VERSION ""

NS_ :

BS_:

BU_: Gas_Snsr ABS EHBL LSC RSC HU BCM MCU BMS OBC
VAL_TABLE_ Theft_Detection_Enum 3 "Error" 2 "Theft_detected" 1 "No_theft_detected" 0 "SNA" ;
VAL_TABLE_ Reset_reason_Enum 4 "WTDG" 3 "SoftReset" 2 "HardReset" 1 "PowerOFF" 0 "SNA" ;
VAL_TABLE_ Wakeup_Reason_Enum 6 "IMU" 5 "Charger" 4 "RTC" 3 "LTE" 2 "BLE" 1 "SSB" 0 "SNA" ;
VAL_TABLE_ Tow_Tamper 2 "Tamper_Detected" 1 "Tow_Detected" 0 "No_Detection" ;
VAL_TABLE_ Crash 3 "High_Crash_Detected" 2 "Mid_Crash_Detected" 1 "Low_Crash_Detected" 0 "No_Crash" ;
VAL_TABLE_ Indicator_Flts 8 "LI_SC_RI_OC_Err" 7 "LI_OC_RI_SC_Err" 6 "LI_RI_SC_Err" 5 "LI_RI_OC_Err" 4 "RI_SC_Err" 3 "RI_OC_Err" 2 "LI_SC_Err" 1 "LI_OC_Err" 0 "No_Err" ;
VAL_TABLE_ Ride_mode_Limp 7 "LIMPHOME" 6 "OFFROAD" 5 "SPORT" 4 "CUSTOM" 3 "TOUR" 2 "RAIN" 1 "ECO" 0 "SNA" ;
VAL_TABLE_ Chrg_Amt 7 "100%" 6 "90%" 5 "80%" 4 "70%" 3 "60%" 2 "50%" 1 "40%" 0 "No_Sel" ;
VAL_TABLE_ Chrg_Rate 3 "Tickle" 2 "Standard" 1 "Rapid" 0 "No_Sel" ;
VAL_TABLE_ MSC_Cntrl_Mode 3 "Reserved" 2 "MTC Control Required" 1 "MDTC Control Required" 0 "No Control Required" ;
VAL_TABLE_ MTC_Lamp 6 "Signal Invalid" 5 "Cornering TC Fail" 4 "TC_User_Disabled" 3 "TC_Initialising" 2 "TC Error" 1 "TC Active Intervention" 0 "TC Not Active" ;
VAL_TABLE_ MTC_Mode 3 "High" 2 "Standard" 1 "Minimum" 0 "OFF" ;
VAL_TABLE_ Allowed 1 "Allowed" 0 "Denied" ;
VAL_TABLE_ Error 1 "Error" 0 "No Error" ;
VAL_TABLE_ Fault 1 "Fault" 0 "No Fault" ;
VAL_TABLE_ InProgress 3 "Invalid" 2 "Completed" 1 "InProgress" 0 "Not Active" ;
VAL_TABLE_ Valid 1 "Valid" 0 "Not Valid" ;
VAL_TABLE_ True_False 1 "True" 0 "False" ;
VAL_TABLE_ SNA_UNLOCK 1 "UNLOCK" 0 "SNA" ;
VAL_TABLE_ OFF_ON 1 "ON" 0 "OFF" ;
VAL_TABLE_ Ride_mode 6 "OFFROAD" 5 "SPORT" 4 "CUSTOM" 3 "TOUR" 2 "RAIN" 1 "ECO" 0 "SNA" ;
VAL_TABLE_ Wireless_Ch 6 "Phone_Overheating" 5 "Charger_Error" 4 "Foreign_Object_Detection" 3 "Charging" 2 "Charging_Completed" 1 "Standby" 0 "SNA" ;
VAL_TABLE_ Language_stt 6 "POR" 5 "ESP" 4 "FR" 3 "DE" 2 "US" 1 "UK" 0 "SNA" ;
VAL_TABLE_ SSB_Illumination_Mode 7 "
EHBL_Lock_Fail" 6 "EHBL_Lock_Success" 5 "Charging_Complete
" 4 "Charging_Mode" 3 "Drive_Mode
" 2 "Park_Mode" 1 "Power_On
" 0 "SNA" ;

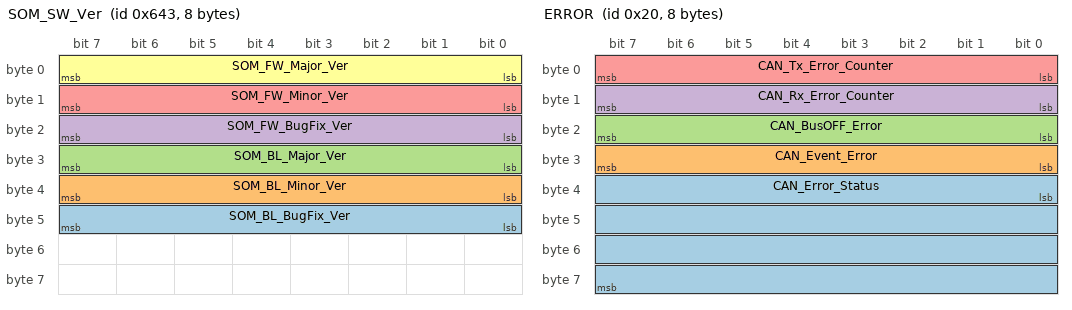
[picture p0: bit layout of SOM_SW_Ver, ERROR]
BO_ 1603 SOM_SW_Ver: 8 BCM
 SG_ SOM_BL_BugFix_Ver : 40|8@1+ (1,0) [0|255] "" Vector__XXX
 SG_ SOM_BL_Minor_Ver : 32|8@1+ (1,0) [0|255] "" Vector__XXX
 SG_ SOM_BL_Major_Ver : 24|8@1+ (1,0) [0|255] "" Vector__XXX
 SG_ SOM_FW_BugFix_Ver : 16|8@1+ (1,0) [0|255] "" Vector__XXX
 SG_ SOM_FW_Minor_Ver : 8|8@1+ (1,0) [0|255] "" Vector__XXX
 SG_ SOM_FW_Major_Ver : 0|8@1+ (1,0) [0|255] "" Vector__XXX

BO_ 1800 VCU_Data10: 8 BCM
 SG_ Reset_reason : 8|8@1+ (1,0) [0|255] "" Vector__XXX
 SG_ Wakeup_reason : 0|8@1+ (1,0) [0|255] "" Vector__XXX

BO_ 772 Diag: 8 BCM
 SG_ Diag : 0|8@1+ (1,0) [0|255] "" Vector__XXX

BO_ 32 ERROR: 8 BCM
 SG_ CAN_Error_Status : 32|32@1- (1,0) [0|0] "" Vector__XXX
 SG_ CAN_Event_Error : 24|8@1- (1,0) [0|0] "" Vector__XXX
 SG_ CAN_BusOFF_Error : 16|8@1- (1,0) [0|0] "" Vector__XXX
 SG_ CAN_Rx_Error_Counter : 8|8@1- (1,0) [0|0] "" Vector__XXX
 SG_ CAN_Tx_Error_Counter : 0|8@1- (1,0) [0|0] "" Vector__XXX

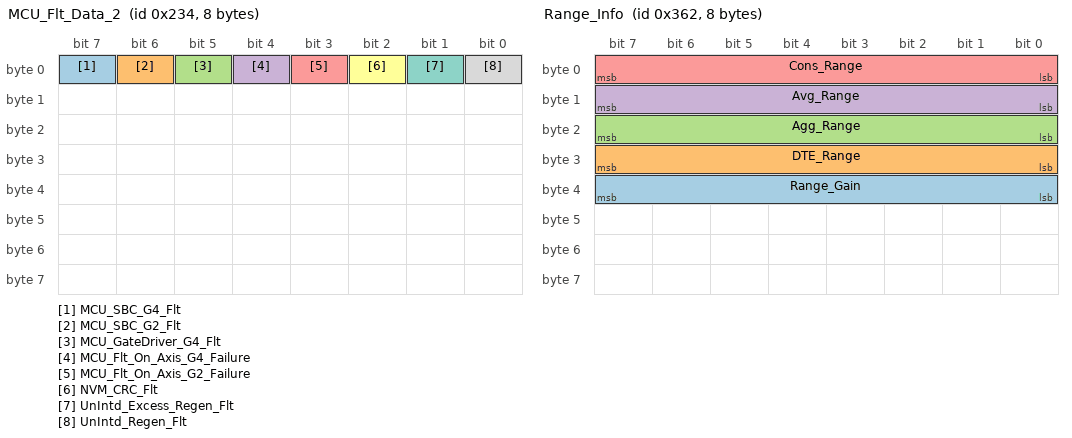
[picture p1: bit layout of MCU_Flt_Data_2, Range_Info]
BO_ 564 MCU_Flt_Data_2: 8 MCU
 SG_ MCU_SBC_G4_Flt : 7|1@1+ (1,0) [0|1] ""  BCM,HU
 SG_ MCU_SBC_G2_Flt : 6|1@1+ (1,0) [0|1] ""  BCM,HU
 SG_ MCU_GateDriver_G4_Flt : 5|1@1+ (1,0) [0|1] ""  BCM,HU
 SG_ MCU_Flt_On_Axis_G4_Failure : 4|1@1+ (1,0) [0|1] ""  BCM,HU
 SG_ MCU_Flt_On_Axis_G2_Failure : 3|1@1+ (1,0) [0|1] ""  BCM,HU
 SG_ NVM_CRC_Flt : 2|1@1+ (1,0) [0|1] ""  BCM,HU
 SG_ UnIntd_Excess_Regen_Flt : 1|1@1+ (1,0) [0|1] ""  BCM,HU
 SG_ UnIntd_Regen_Flt : 0|1@1+ (1,0) [0|1] ""  BCM,HU

BO_ 769 CS1_HSD: 8 BCM
 SG_ CS_Parameter4 : 48|16@1+ (1,0) [0|65535] "mV" Vector__XXX
 SG_ CS_Parameter3 : 32|16@1+ (1,0) [0|65535] "mV" Vector__XXX
 SG_ CS_Parameter2 : 16|16@1+ (1,0) [0|65535] "mV" Vector__XXX
 SG_ CS_Parameter1 : 0|16@1+ (1,0) [0|65535] "mV" Vector__XXX

BO_ 2015 Func_Diag_ID: 8 Vector__XXX

BO_ 315 Traction_Info: 8 ABS
 SG_ MDTC_Torque_Req : 32|16@1- (0.01,0) [-327|326] "Nm"  BCM,MCU
 SG_ MTC_Torque_Req : 16|16@1- (0.01,0) [-327|326] "Nm"  BCM,MCU
 SG_ MSC_Trq_Ctrl_mode : 0|2@1+ (1,0) [0|3] ""  MCU,BCM

BO_ 571 MCU_Data_7: 8 MCU
 SG_ Active_ShrtCkt_Sts : 48|2@1+ (1,0) [0|3] ""  BCM
 SG_ MCU_DC_Bus_Vlt_2 : 16|16@1+ (0.01,0) [0|655.35] "V"  BCM
 SG_ MCU_DC_Bus_Vlt_3 : 32|16@1+ (0.01,0) [0|655.35] "V"  BCM
 SG_ MCU_DC_Bus_Vlt_1 : 0|16@1+ (0.01,0) [0|655.35] "V"  BCM

BO_ 866 Range_Info: 8 BCM
 SG_ Range_Gain : 32|8@1+ (1,0) [0|255] "km"  HU
 SG_ DTE_Range : 24|8@1+ (1,0) [0|255] "km"  HU
 SG_ Agg_Range : 16|8@1+ (1,0) [0|255] "km"  HU
 SG_ Avg_Range : 8|8@1+ (1,0) [0|255] "km"  HU
 SG_ Cons_Range : 0|8@1+ (1,0) [0|255] "km"  HU

BO_ 2023 BCM_Diagnostic_Request: 8 Vector__XXX
 SG_ BCM_Diag_Request : 0|64@1+ (1,0) [0|1.84467440737096E+19] ""  BCM

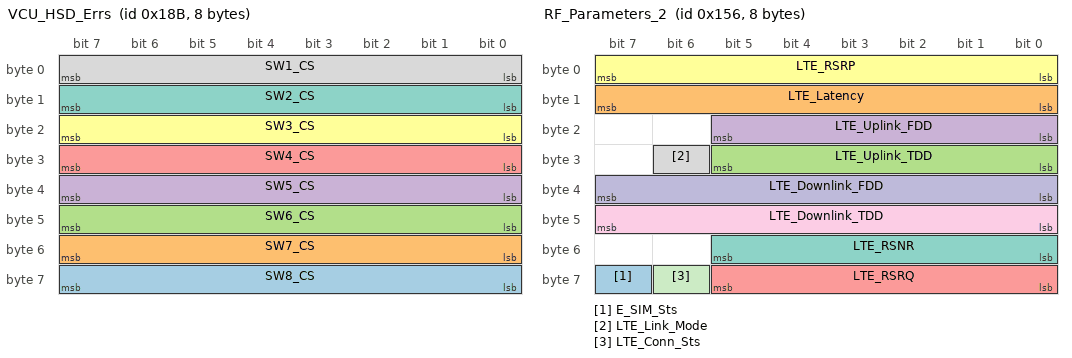
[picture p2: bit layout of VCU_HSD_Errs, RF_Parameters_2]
BO_ 395 VCU_HSD_Errs: 8 BCM
 SG_ SW8_CS : 56|8@1+ (1,0) [0|255] "" Vector__XXX
 SG_ SW7_CS : 48|8@1+ (1,0) [0|255] "" Vector__XXX
 SG_ SW6_CS : 40|8@1+ (1,0) [0|255] "" Vector__XXX
 SG_ SW5_CS : 32|8@1+ (1,0) [0|255] "" Vector__XXX
 SG_ SW4_CS : 24|8@1+ (1,0) [0|255] "" Vector__XXX
 SG_ SW3_CS : 16|8@1+ (1,0) [0|255] "" Vector__XXX
 SG_ SW2_CS : 8|8@1+ (1,0) [0|255] "" Vector__XXX
 SG_ SW1_CS : 0|8@1+ (1,0) [0|255] "" Vector__XXX

BO_ 342 RF_Parameters_2: 8 BCM
 SG_ E_SIM_Sts : 63|1@1+ (1,0) [0|1] "" Vector__XXX
 SG_ LTE_Latency : 8|8@1+ (1,0) [0|255] "ms" Vector__XXX
 SG_ LTE_Uplink_TDD : 24|6@1+ (1,0) [0|63] "mbps" Vector__XXX
 SG_ LTE_Uplink_FDD : 16|6@1+ (1,0) [0|63] "mbps" Vector__XXX
 SG_ LTE_RSRQ : 56|6@1+ (1,-60) [-60|3] "dB" Vector__XXX
 SG_ LTE_RSRP : 0|8@1+ (1,-120) [-120|135] "dBm" Vector__XXX
 SG_ LTE_RSNR : 48|6@1+ (1,0) [0|63] "mbps" Vector__XXX
 SG_ LTE_Link_Mode : 30|1@1+ (1,0) [0|1] "" Vector__XXX
 SG_ LTE_Downlink_TDD : 40|8@1+ (1,0) [0|255] "mbps" Vector__XXX
 SG_ LTE_Downlink_FDD : 32|8@1+ (1,0) [0|255] "mbps" Vector__XXX
 SG_ LTE_Conn_Sts : 62|1@1+ (1,0) [0|1] "" Vector__XXX

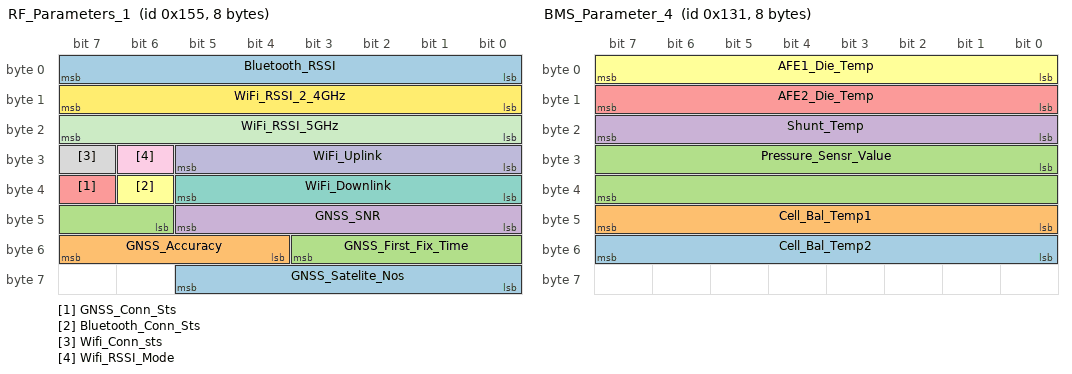
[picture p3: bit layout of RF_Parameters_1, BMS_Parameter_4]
BO_ 341 RF_Parameters_1: 8 BCM
 SG_ GNSS_Satelite_Nos : 56|6@1+ (1,0) [0|63] "" Vector__XXX
 SG_ GNSS_Accuracy : 52|4@1+ (1,0) [0|15] "m" Vector__XXX
 SG_ GNSS_First_Fix_Time : 46|6@1+ (1,0) [0|63] "secs" Vector__XXX
 SG_ GNSS_SNR : 40|6@1+ (1,-60) [-60|3] "dB" Vector__XXX
 SG_ GNSS_Conn_Sts : 39|1@1+ (1,0) [0|1] "" Vector__XXX
 SG_ Bluetooth_Conn_Sts : 38|1@1+ (1,0) [0|1] "" Vector__XXX
 SG_ WiFi_Downlink : 32|6@1+ (1,0) [0|63] "mbps" Vector__XXX
 SG_ Wifi_Conn_sts : 31|1@1+ (1,0) [0|1] "" Vector__XXX
 SG_ Wifi_RSSI_Mode : 30|1@1+ (1,0) [0|1] "" Vector__XXX
 SG_ WiFi_Uplink : 24|6@1+ (1,0) [0|63] "mbps" Vector__XXX
 SG_ WiFi_RSSI_5GHz : 16|8@1+ (1,-120) [-120|135] "dBm" Vector__XXX
 SG_ WiFi_RSSI_2_4GHz : 8|8@1+ (1,-120) [-120|135] "dBm" Vector__XXX
 SG_ Bluetooth_RSSI : 0|8@1+ (1,-120) [-120|135] "dBm" Vector__XXX

BO_ 305 BMS_Parameter_4: 8 BMS
 SG_ Cell_Bal_Temp2 : 48|8@1+ (1,-40) [-40|150] "degC"  BCM
 SG_ Cell_Bal_Temp1 : 40|8@1+ (1,-40) [-40|150] "degC"  BCM
 SG_ Pressure_Sensr_Value : 24|16@1+ (1,0) [0|315] "kPa"  BCM
 SG_ Shunt_Temp : 16|8@1+ (1,-20) [-20|120] "degC"  BCM
 SG_ AFE2_Die_Temp : 8|8@1+ (1,-40) [-40|150] "degC"  BCM
 SG_ AFE1_Die_Temp : 0|8@1+ (1,-40) [-40|150] "degC"  BCM

BO_ 394 VCU_Data9: 8 BCM
 SG_ Instant_Eff : 16|16@1+ (0.1,0) [0|6553.5] "Wh/Km"  HU
 SG_ Live_Odo : 0|16@1+ (0.1,0) [0|6553.5] "Km"  HU

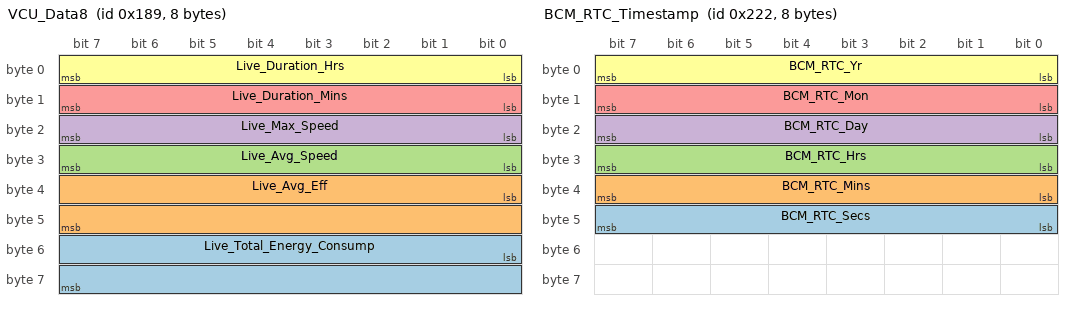
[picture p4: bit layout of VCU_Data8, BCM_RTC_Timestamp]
BO_ 393 VCU_Data8: 8 BCM
 SG_ Live_Total_Energy_Consump : 48|16@1+ (0.1,0) [0|6553.5] "kWh"  HU
 SG_ Live_Avg_Eff : 32|16@1+ (0.1,0) [0|6553.5] "Wh/Km"  HU
 SG_ Live_Avg_Speed : 24|8@1+ (1,0) [0|255] "Kmph"  HU
 SG_ Live_Max_Speed : 16|8@1+ (1,0) [0|255] "Kmph"  HU
 SG_ Live_Duration_Mins : 8|8@1+ (1,0) [0|255] "Mins"  HU
 SG_ Live_Duration_Hrs : 0|8@1+ (1,0) [0|255] "hrs"  HU

BO_ 546 BCM_RTC_Timestamp: 8 BCM
 SG_ BCM_RTC_Secs : 40|8@1+ (1,0) [0|255] ""  HU
 SG_ BCM_RTC_Mins : 32|8@1+ (1,0) [0|255] ""  HU
 SG_ BCM_RTC_Hrs : 24|8@1+ (1,0) [0|255] ""  HU
 SG_ BCM_RTC_Day : 16|8@1+ (1,0) [0|255] ""  HU
 SG_ BCM_RTC_Mon : 8|8@1+ (1,0) [0|255] ""  HU
 SG_ BCM_RTC_Yr : 0|8@1+ (1,0) [0|255] ""  HU

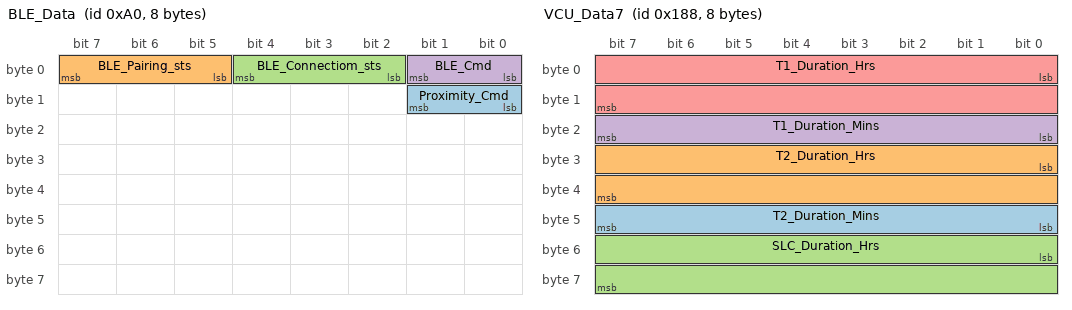
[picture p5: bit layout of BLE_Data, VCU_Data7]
BO_ 160 BLE_Data: 8 BCM
 SG_ Proximity_Cmd : 8|2@1+ (1,0) [0|3] "" Vector__XXX
 SG_ BLE_Pairing_sts : 5|3@1+ (1,0) [0|7] "" Vector__XXX
 SG_ BLE_Connectiom_sts : 2|3@1+ (1,0) [0|7] "" Vector__XXX
 SG_ BLE_Cmd : 0|2@1+ (1,0) [0|3] "" Vector__XXX

BO_ 392 VCU_Data7: 8 BCM
 SG_ T2_Duration_Mins : 40|8@1+ (1,0) [0|255] "mins"  HU
 SG_ T2_Duration_Hrs : 24|16@1+ (1,0) [0|65535] "hrs"  HU
 SG_ SLC_Duration_Hrs : 48|16@1+ (1,0) [0|65535] "hrs"  HU
 SG_ T1_Duration_Mins : 16|8@1+ (1,0) [0|255] "Mins"  HU
 SG_ T1_Duration_Hrs : 0|16@1+ (1,0) [0|65535] "hrs"  HU

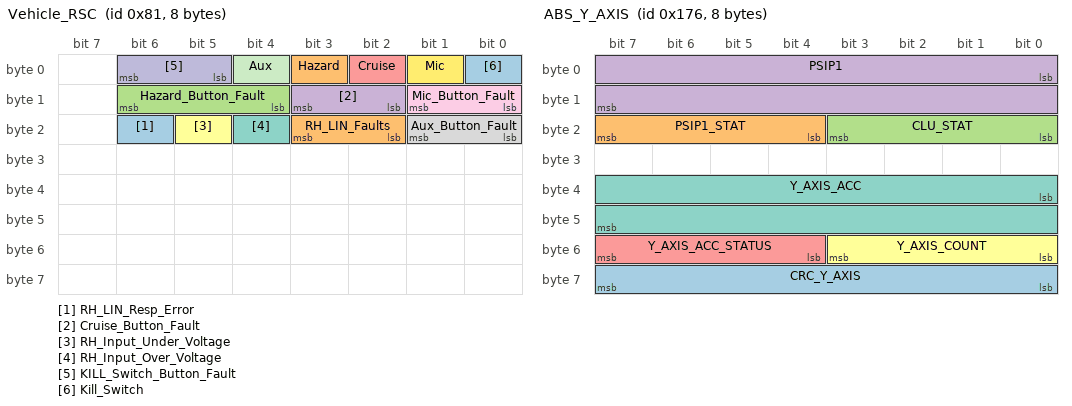
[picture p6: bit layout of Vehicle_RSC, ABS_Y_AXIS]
BO_ 129 Vehicle_RSC: 8 BCM
 SG_ RH_LIN_Resp_Error : 22|1@1+ (1,0) [0|1] "" Vector__XXX
 SG_ RH_LIN_Faults : 18|2@1+ (1,0) [0|3] "" Vector__XXX
 SG_ Hazard_Button_Fault : 12|3@1+ (1,0) [0|3] "" Vector__XXX
 SG_ Cruise_Button_Fault : 10|2@1+ (1,0) [0|1] "" Vector__XXX
 SG_ Cruise : 2|1@1+ (1,0) [0|1] "" Vector__XXX
 SG_ RH_Input_Under_Voltage : 21|1@1+ (1,0) [0|1] "" Vector__XXX
 SG_ RH_Input_Over_Voltage : 20|1@1+ (1,0) [0|1] "" Vector__XXX
 SG_ Aux_Button_Fault : 16|2@1+ (1,0) [0|3] "" Vector__XXX
 SG_ Mic_Button_Fault : 8|2@1+ (1,0) [0|3] "" Vector__XXX
 SG_ KILL_Switch_Button_Fault : 5|2@1+ (1,0) [0|3] "" Vector__XXX
 SG_ Aux : 4|1@1+ (1,0) [0|1] "" Vector__XXX
 SG_ Mic : 1|1@1+ (1,0) [0|1] "" Vector__XXX
 SG_ Kill_Switch : 0|1@1+ (1,0) [0|1] "" Vector__XXX
 SG_ Hazard : 3|1@1+ (1,0) [0|1] "" Vector__XXX

BO_ 128 Vehicle_LSC: 8 BCM
 SG_ LH_LIN_Resp_Error : 60|1@1+ (1,0) [0|1] "" Vector__XXX
 SG_ LH_LIN_Faults : 56|2@1+ (1,0) [0|7] "" Vector__XXX
 SG_ Mode_Down_Button_Fault : 43|3@1+ (1,0) [0|3] "" Vector__XXX
 SG_ Mode_Up_Button_Fault : 40|3@1+ (1,0) [0|3] "" Vector__XXX
 SG_ Pass_Beam_Button_Fault : 24|3@1+ (1,0) [0|3] "" Vector__XXX
 SG_ High_Beam_Button_Fault : 19|3@1+ (1,0) [0|3] "" Vector__XXX
 SG_ Home_Button_Fault : 16|3@1+ (1,0) [0|3] "" Vector__XXX
 SG_ LH_Input_Under_Voltage : 59|1@1+ (1,0) [0|1] "" Vector__XXX
 SG_ LH_Input_Over_Voltage : 58|1@1+ (1,0) [0|1] "" Vector__XXX
 SG_ RH_Ind_Button_Fault : 52|2@1+ (1,0) [0|3] "" Vector__XXX
 SG_ LH_Ind_Button_Fault : 50|2@1+ (1,0) [0|3] "" Vector__XXX
 SG_ Ok_Button_Fault : 48|2@1+ (1,0) [0|3] "" Vector__XXX
 SG_ Right_JoyStick_Button_Fault : 34|2@1+ (1,0) [0|3] "" Vector__XXX
 SG_ Up_JoyStick_Button_Fault : 36|2@1+ (1,0) [0|3] "" Vector__XXX
 SG_ Left_JoyStick_Button_Fault : 32|2@1+ (1,0) [0|3] "" Vector__XXX
 SG_ Horn_Button_Fault : 13|2@1+ (1,0) [0|3] "" Vector__XXX
 SG_ Down_JoyStick_Button_Fault : 38|2@1+ (1,0) [0|3] "" Vector__XXX
 SG_ RH_Ind : 12|1@1+ (1,0) [0|1] "" Vector__XXX
 SG_ LH_Ind : 11|1@1+ (1,0) [0|1] "" Vector__XXX
 SG_ OK_Btn : 10|1@1+ (1,0) [0|1] "" Vector__XXX
 SG_ Mode_Dwn_Selector : 9|1@1+ (1,0) [0|1] "" Vector__XXX
 SG_ Mode_Up_Selector : 8|1@1+ (1,0) [0|1] "" Vector__XXX
 SG_ Down_Joy_Stick : 7|1@1+ (1,0) [0|1] "" Vector__XXX
 SG_ Up_Joy_Stick : 6|1@1+ (1,0) [0|1] "" Vector__XXX
 SG_ Right_Joy_Stick : 5|1@1+ (1,0) [0|1] "" Vector__XXX
 SG_ Left_Joy_Stick : 4|1@1+ (1,0) [0|1] "" Vector__XXX
 SG_ Pass_beam : 3|1@1+ (1,0) [0|1] "" Vector__XXX
 SG_ High_beam : 2|1@1+ (1,0) [0|1] "" Vector__XXX
 SG_ Home : 1|1@1+ (1,0) [0|1] "" Vector__XXX
 SG_ Horn : 0|1@1+ (1,0) [0|1] "" Vector__XXX

BO_ 374 ABS_Y_AXIS: 8 ABS
 SG_ CRC_Y_AXIS : 56|8@1+ (1,0) [0|255] ""  BCM
 SG_ PSIP1_STAT : 20|4@1+ (1,0) [0|15] ""  BCM
 SG_ CLU_STAT : 16|4@1+ (1,0) [0|15] ""  BCM
 SG_ PSIP1 : 0|16@1+ (0.005,-163.84) [-163.84|163.835] "deg/sec"  BCM
 SG_ Y_AXIS_ACC_STATUS : 52|4@1+ (1,0) [0|15] ""  BCM
 SG_ Y_AXIS_COUNT : 48|4@1+ (1,0) [0|15] ""  BCM
 SG_ Y_AXIS_ACC : 32|16@1+ (0.00125,-40.957) [-40.957|40.958] "m/s^2"  BCM

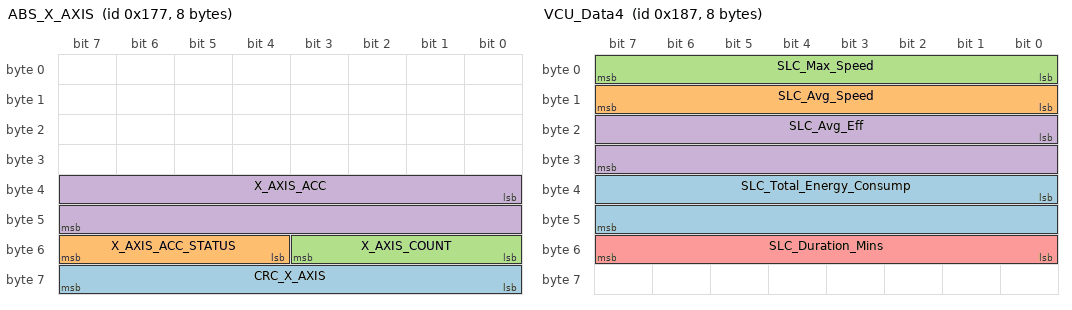
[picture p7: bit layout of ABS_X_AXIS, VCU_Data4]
BO_ 375 ABS_X_AXIS: 8 ABS
 SG_ CRC_X_AXIS : 56|8@1+ (1,0) [0|255] ""  BCM
 SG_ X_AXIS_ACC_STATUS : 52|4@1+ (1,0) [0|15] ""  BCM
 SG_ X_AXIS_COUNT : 48|4@1+ (1,0) [0|15] ""  BCM
 SG_ X_AXIS_ACC : 32|16@1+ (0.00125,-40.957) [-40.957|40.958] "m/s^2"  BCM

BO_ 565 MCU_Data_6: 8 MCU
 SG_ OnAxix_3_3_Vlt : 16|8@1+ (0.1,0) [0|25.5] "V"  BCM
 SG_ Regen_sts : 8|3@1+ (1,0) [0|4] ""  BCM,HU
 SG_ Motor_Power : 0|8@1+ (1,0) [0|255] "Kw"  HU,BCM

BO_ 391 VCU_Data4: 8 BCM
 SG_ SLC_Total_Energy_Consump : 32|16@1+ (0.1,0) [0|6553.5] "kWh"  HU
 SG_ SLC_Avg_Speed : 8|8@1+ (1,0) [0|255] "Kmph"  HU
 SG_ SLC_Max_Speed : 0|8@1+ (1,0) [0|255] "Kmph"  HU
 SG_ SLC_Avg_Eff : 16|16@1+ (0.1,0) [0|6553.5] "Wh/Km"  HU
 SG_ SLC_Duration_Mins : 48|8@1+ (1,0) [0|255] "Mins"  HU

BO_ 390 VCU_Data3: 8 BCM
 SG_ T2_Avg_Eff : 16|16@1+ (0.1,0) [0|6553.5] "Wh/Km"  HU
 SG_ T2_Avg_Speed : 8|8@1+ (1,0) [0|255] "Kmph"  HU
 SG_ T2_Max_Speed : 0|8@1+ (1,0) [0|255] "Kmph"  HU
 SG_ T2_Total_Energy_Consump : 32|16@1+ (0.1,0) [0|6553.5] "kWh"  HU

BO_ 373 VCU_Data2: 8 BCM
 SG_ T1_Total_Energy_Consump : 32|16@1+ (0.1,0) [0|6553.5] "kWh"  HU
 SG_ T1_Avg_Eff : 16|16@1+ (0.1,0) [0|6553.5] "Wh/Km"  HU
 SG_ T1_Avg_Speed : 8|8@1+ (1,0) [0|255] "Kmph"  HU
 SG_ T1_Max_Speed : 0|8@1+ (1,0) [0|255] "Kmph"  HU

BO_ 377 VCU_Data6: 8 BCM
 SG_ Trip2_Odo : 32|32@1+ (0.1,0) [0|429496729.5] "Km"  HU
 SG_ Trip1_Odo : 0|32@1+ (0.1,0) [0|429496729.5] "Km"  HU

BO_ 376 VCU_Data5: 8 BCM
 SG_ SLC_Odo : 32|32@1+ (0.1,0) [0|429496729.5] "Km"  HU
 SG_ Odometer : 0|32@1+ (1,0) [0|4294967295] "Km"  HU

BO_ 1229 EHBL_SW_VER: 8 EHBL
 SG_ EHBL_FW_BugFix_Ver : 16|8@1+ (1,0) [0|255] ""  BCM
 SG_ EHBL_FW_Minor_Ver : 8|8@1+ (1,0) [0|255] ""  BCM
 SG_ EHBL_FW_Major_Ver : 0|8@1+ (1,0) [0|255] ""  BCM

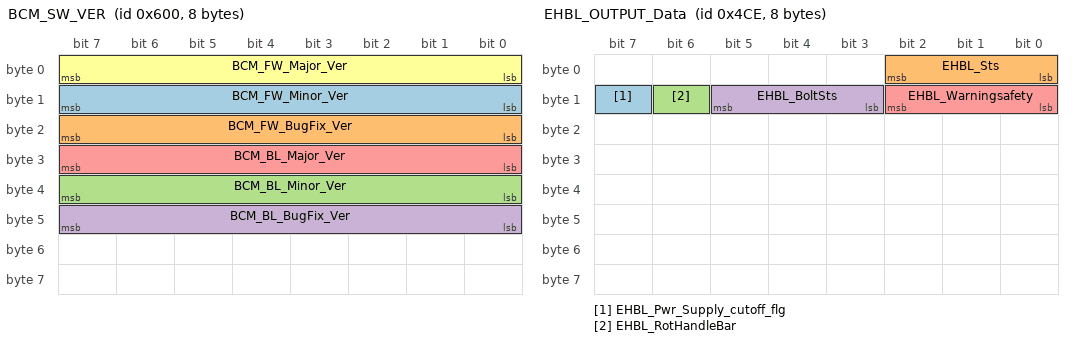
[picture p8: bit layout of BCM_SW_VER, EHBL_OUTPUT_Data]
BO_ 1536 BCM_SW_VER: 8 BCM
 SG_ BCM_FW_Minor_Ver : 8|8@1+ (1,0) [0|255] "" Vector__XXX
 SG_ BCM_FW_BugFix_Ver : 16|8@1+ (1,0) [0|255] "" Vector__XXX
 SG_ BCM_BL_Minor_Ver : 32|8@1+ (1,0) [0|255] "" Vector__XXX
 SG_ BCM_BL_BugFix_Ver : 40|8@1+ (1,0) [0|255] "" Vector__XXX
 SG_ BCM_BL_Major_Ver : 24|8@1+ (1,0) [0|255] "" Vector__XXX
 SG_ BCM_FW_Major_Ver : 0|8@1+ (1,0) [0|255] "" Vector__XXX

BO_ 1230 EHBL_OUTPUT_Data: 8 EHBL
 SG_ EHBL_Pwr_Supply_cutoff_flg : 15|1@1+ (1,0) [0|1] ""  BCM
 SG_ EHBL_Sts : 0|3@1+ (1,0) [0|7] ""  BCM
 SG_ EHBL_RotHandleBar : 14|1@1+ (1,0) [0|1] ""  BCM
 SG_ EHBL_BoltSts : 11|3@1+ (1,0) [0|7] ""  BCM
 SG_ EHBL_Warningsafety : 8|3@1+ (1,0) [0|7] ""  BCM

BO_ 1618 EHBL_to_VCU_Auth_Response: 8 EHBL
 SG_ EHBL_Auth_Result : 8|8@1+ (1,0) [0|255] ""  BCM

BO_ 1104 VCU_TO_ABS: 8 BCM
 SG_ MTC_Requested_Mode : 8|3@1+ (1,0) [0|4] ""  ABS
 SG_ ABS_Requested_Mode : 4|4@1+ (1,0) [0|15] ""  ABS
 SG_ Variant_Info : 0|4@1+ (1,0) [0|15] ""  ABS

BO_ 576 ABS_Flt_Info: 8 ABS
 SG_ IMU_Model_Monitoring : 23|1@1+ (1,0) [0|1] ""  BCM
 SG_ IMU_Wrong_Mount_Fail : 22|1@1+ (1,0) [0|1] ""  BCM
 SG_ CAN_Buss_Off_Fail : 17|1@1+ (1,0) [0|1] ""  BCM
 SG_ CAN_IMU_Signal_Fail : 21|1@1+ (1,0) [0|1] ""  BCM
 SG_ CAN_IMU_Frame_Fail : 20|1@1+ (1,0) [0|1] ""  BCM
 SG_ CAN_Frame : 19|1@1+ (1,0) [0|1] ""  BCM
 SG_ CAN_Controller_Generic_Fail : 18|1@1+ (1,0) [0|1] ""  BCM
 SG_ WSS_Generic_Fail : 16|1@1+ (1,0) [0|1] ""  BCM
 SG_ WSS_Suspicious_Fail_R : 15|1@1+ (1,0) [0|1] ""  BCM
 SG_ WSS_Suspicious_Fail_F : 14|1@1+ (1,0) [0|1] ""  BCM
 SG_ WSS_Plausibility_Fail_R : 13|1@1+ (1,0) [0|1] ""  BCM
 SG_ WSS_Plausibility_Fail_F : 12|1@1+ (1,0) [0|1] ""  BCM
 SG_ WSS_HW_Fail_R : 11|1@1+ (1,0) [0|1] ""  BCM
 SG_ WSS_HW_Fail_F : 10|1@1+ (1,0) [0|1] ""  BCM
 SG_ Pump_Motor_Reversible_Fail : 9|1@1+ (1,0) [0|1] ""  BCM
 SG_ Pump_Motor_Fail : 8|1@1+ (1,0) [0|1] ""  BCM
 SG_ UZ_Supply_UV_Flt : 7|1@1+ (1,0) [0|1] ""  BCM
 SG_ UZ_Supply_OV_Flt : 6|1@1+ (1,0) [0|1] ""  BCM
 SG_ Outlet_Valve_Fail_R : 5|1@1+ (1,0) [0|1] ""  BCM
 SG_ Outlet_Valve_Fail_F : 4|1@1+ (1,0) [0|1] ""  BCM
 SG_ Inlet_Valve_Fail_R : 3|1@1+ (1,0) [0|1] ""  BCM
 SG_ Inlet_Valve_Fail_F : 2|1@1+ (1,0) [0|1] ""  BCM
 SG_ Valve_Relay_Flt : 1|1@1+ (1,0) [0|1] ""  BCM
 SG_ Control_Unit_Fail : 0|1@1+ (1,0) [0|1] ""  BCM

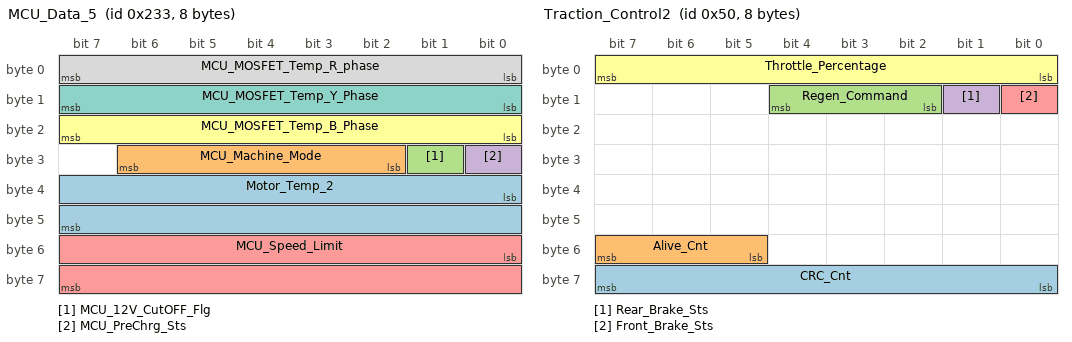
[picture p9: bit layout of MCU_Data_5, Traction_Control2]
BO_ 563 MCU_Data_5: 8 MCU
 SG_ Motor_Temp_2 : 32|16@1+ (0.01,-55) [-55|600.35] "degC"  BCM
 SG_ MCU_Machine_Mode : 26|5@1+ (1,0) [0|31] ""  HU,BCM
 SG_ MCU_12V_CutOFF_Flg : 25|1@1+ (1,0) [0|1] ""  BCM
 SG_ MCU_PreChrg_Sts : 24|1@1+ (1,0) [0|1] ""  BCM
 SG_ MCU_Speed_Limit : 48|16@1- (1,0) [-32768|32767] ""  BCM
 SG_ MCU_MOSFET_Temp_B_Phase : 16|8@1+ (1,-55) [-55|200] ""  BCM
 SG_ MCU_MOSFET_Temp_Y_Phase : 8|8@1+ (1,-55) [-55|200] ""  BCM
 SG_ MCU_MOSFET_Temp_R_phase : 0|8@1+ (1,-55) [-55|200] ""  BCM

BO_ 343 ISOLATION_Resistance_Monitor: 8 BMS
 SG_ Neg_Isolation_Resistance : 32|32@1+ (1,0) [0|4294967295] "Ohm"  BCM
 SG_ Pos_Isolation_Resistance : 0|32@1+ (1,0) [0|4294967295] "Ohm"  BCM

BO_ 340 SOM_Settings_Data: 8 BCM
 SG_ Theft_Detection : 38|2@1+ (1,0) [0|3] "" Vector__XXX
 SG_ SOM_CRateSel_PreConf : 30|2@1+ (1,0) [0|3] "" Vector__XXX
 SG_ SOM_Boot_Ack : 7|1@1+ (1,0) [0|1] "" Vector__XXX
 SG_ SOM_ChrgAmtSel_PreConf : 48|4@1+ (1,0) [0|15] "" Vector__XXX
 SG_ SOM_Chrg_Amt_Sel : 12|4@1+ (1,0) [0|15] "" Vector__XXX
 SG_ SOM_Chrg_Rate_Sel : 5|2@1+ (1,0) [0|3] "" Vector__XXX
 SG_ Language_Sel_Set : 8|3@1+ (1,0) [0|6] ""  HU
 SG_ Vacation_Mode : 0|1@1+ (1,0) [0|1] "" Vector__XXX
 SG_ Brightness_Level : 42|4@1+ (1,0) [0|15] ""  HU
 SG_ Trip_2_Reset_flg : 41|1@1+ (1,0) [0|1] "" Vector__XXX
 SG_ Trip_1_Reset_flg : 40|1@1+ (1,0) [0|1] "" Vector__XXX
 SG_ Day_Night_Mode_Sel : 46|2@1+ (1,0) [0|3] ""  HU
 SG_ Brightness_Sel : 2|1@1+ (1,0) [0|1] ""  HU
 SG_ ABS_Sensitivity_Sel : 21|2@1+ (1,0) [0|3] "" Vector__XXX
 SG_ ABS_State_Sel : 19|2@1+ (1,0) [0|3] ""  HU
 SG_ TPMS_Rear : 32|6@1+ (1,0) [0|63] "" Vector__XXX
 SG_ TPMS_Front : 24|6@1+ (1,0) [0|63] "" Vector__XXX
 SG_ Ride_Mode_Sel : 16|3@1+ (1,0) [0|7] "" Vector__XXX
 SG_ Hill_Hold_Setting : 4|1@1+ (1,0) [0|1] ""  ABS
 SG_ Haptic_Setting : 3|1@1+ (1,0) [0|1] "" Vector__XXX
 SG_ Regen_Setting : 1|1@1+ (1,0) [0|1] ""  ABS

BO_ 561 MCU_Data_3: 8 MCU
 SG_ Regen_Min_Speed : 48|14@1+ (1,0) [0|16383] "rpm"  BCM
 SG_ B_Phase_Curr_MCU : 32|16@1- (0.1,0) [-32768|32767] "A"  BCM
 SG_ Y_Phase_Curr_MCU : 16|16@1- (0.1,0) [-32768|32767] "A"  BCM
 SG_ R_Phase_Curr_MCU : 0|16@1- (0.1,0) [-32768|32767] "A"  BCM

BO_ 80 Traction_Control2: 8 BCM
 SG_ CRC_Cnt : 56|8@1+ (1,0) [0|255] ""  ABS
 SG_ Alive_Cnt : 53|3@1+ (1,0) [0|7] ""  ABS
 SG_ Regen_Command : 10|3@1+ (1,0) [0|4] ""  MCU
 SG_ Rear_Brake_Sts : 9|1@1+ (1,0) [0|1] ""  MCU
 SG_ Front_Brake_Sts : 8|1@1+ (1,0) [0|1] ""  MCU
 SG_ Throttle_Percentage : 0|8@1- (1,0) [-128|127] "%"  ABS,MCU

BO_ 2031 BCM_Diagnostic_Response: 8 BCM
 SG_ BCM_Diag_Response : 0|64@1+ (1,0) [0|1.84467440737096E+19] "" Vector__XXX

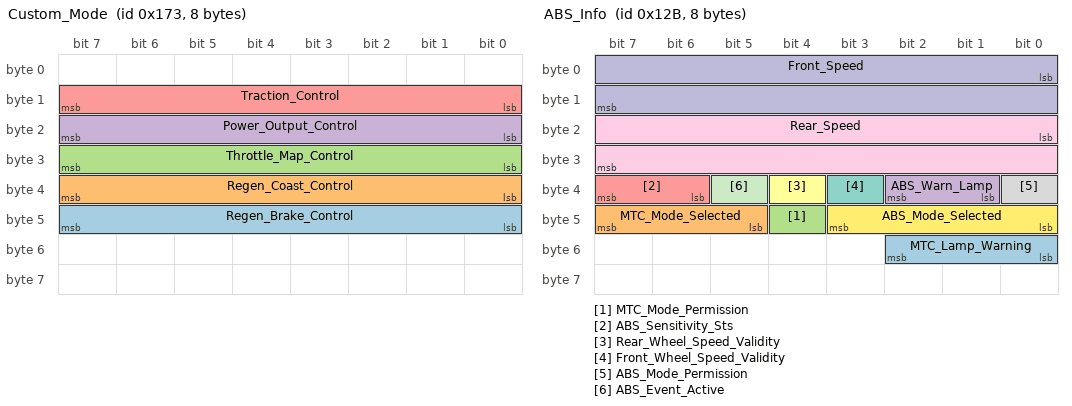
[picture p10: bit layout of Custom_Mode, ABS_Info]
BO_ 371 Custom_Mode: 8 BCM
 SG_ Regen_Brake_Control : 40|8@1+ (1,0) [0|255] ""  MCU
 SG_ Regen_Coast_Control : 32|8@1+ (1,0) [0|255] ""  MCU
 SG_ Throttle_Map_Control : 24|8@1+ (1,0) [0|255] ""  MCU
 SG_ Power_Output_Control : 16|8@1+ (1,0) [0|255] ""  MCU
 SG_ Traction_Control : 8|8@1+ (1,0) [0|255] ""  HU,MCU

BO_ 2027 EHBL_Diagnostic_Response: 8 EHBL
 SG_ EHBL_Diag_Response : 0|64@1+ (1,0) [0|1.84467440737096E+19] ""  BCM

BO_ 299 ABS_Info: 8 ABS
 SG_ MTC_Lamp_Warning : 48|3@1+ (1,0) [0|6] ""  BCM,HU
 SG_ MTC_Mode_Selected : 45|3@1+ (1,0) [0|4] ""  BCM
 SG_ MTC_Mode_Permission : 44|1@1+ (1,0) [0|1] ""  BCM
 SG_ ABS_Warn_Lamp : 33|2@1+ (1,0) [0|3] ""  HU,BCM
 SG_ ABS_Sensitivity_Sts : 38|2@1+ (1,0) [0|3] ""  BCM
 SG_ Rear_Wheel_Speed_Validity : 36|1@1+ (1,0) [0|1] ""  BCM
 SG_ Front_Wheel_Speed_Validity : 35|1@1+ (1,0) [0|1] ""  BCM
 SG_ ABS_Mode_Permission : 32|1@1+ (1,0) [0|1] ""  BCM
 SG_ Rear_Speed : 16|16@1+ (0.05625,0) [0|360] "kmph"  BCM
 SG_ Front_Speed : 0|16@1+ (0.05625,0) [0|360] "kmph"  BCM
 SG_ ABS_Event_Active : 37|1@1+ (1,0) [0|1] ""  BCM
 SG_ ABS_Mode_Selected : 40|4@1+ (1,0) [0|4] ""  HU,BCM

BO_ 1290 BMS_Flt_2: 8 BMS
 SG_ Temp_Imbalance_Warn : 52|1@1+ (1,0) [0|1] ""  BCM,HU
 SG_ BMS_LP_DCDC_Ovload_flt : 51|1@1+ (1,0) [0|1] ""  HU,BCM
 SG_ BMS_Vlt_Imbalance_flt : 50|1@1+ (1,0) [0|1] ""  HU,BCM
 SG_ BMS_Internal_Fault : 49|1@1+ (1,0) [0|1] ""  HU,BCM
 SG_ BMS_Prechrg_Overload : 48|1@1+ (1,0) [0|1] ""  HU,BCM
 SG_ BMS_OV_Permnt_Flt : 47|1@1+ (1,0) [0|1] ""  HU,BCM
 SG_ BMS_UV_Permnt_Flt : 46|1@1+ (1,0) [0|1] ""  HU,BCM
 SG_ Fire_Ext_Sts : 44|1@1+ (1,0) [0|1] ""  HU,BCM
 SG_ Pyro_Fuse_Sts : 43|1@1+ (1,0) [0|1] ""  HU,BCM
 SG_ Low_SOC_Warn_15 : 45|1@1+ (1,0) [0|1] ""  HU,BCM
 SG_ HVIL_OBC_Err : 39|1@1+ (1,0) [0|1] ""  HU,BCM
 SG_ HVIL_MCU_Err : 38|1@1+ (1,0) [0|1] ""  HU,BCM
 SG_ BMS_Dischrg_Fuse_Fail : 35|1@1+ (1,0) [0|1] ""  HU,BCM
 SG_ BMS_Chrgr_Fuse_Fail : 34|1@1+ (1,0) [0|1] ""  HU,BCM
 SG_ LPDCDC_OP_FAIL : 31|1@1+ (1,0) [0|1] ""  HU,BCM
 SG_ AFE1_Fail : 30|1@1+ (1,0) [0|1] ""  HU,BCM
 SG_ Pack_Monitor_Fail : 29|1@1+ (1,0) [0|1] ""  HU,BCM
 SG_ AFE_ISO_Fail_Err : 28|1@1+ (1,0) [0|1] ""  HU,BCM
 SG_ AFE_SPI_Heartbeat_Fail_Err : 27|1@1+ (1,0) [0|1] ""  HU,BCM
 SG_ LOW_SOC : 26|1@1+ (1,0) [0|1] ""  HU,BCM
 SG_ LOW_SOC_WARN : 25|1@1+ (1,0) [0|1] ""  HU,BCM
 SG_ HPDCDC_OP_FAIL : 24|1@1+ (1,0) [0|1] ""  HU,BCM
 SG_ Pos_Contactor_Weld : 23|1@1+ (1,0) [0|1] ""  BCM,HU
 SG_ PreChrg_Relay_Weld : 22|1@1+ (1,0) [0|1] ""  BCM,HU
 SG_ OBC_CAN_Heartbeat_Err : 21|1@1+ (1,0) [0|1] ""  BCM,HU
 SG_ VCU_CAN_Heartbeat_Err : 20|1@1+ (1,0) [0|1] ""  BCM,HU
 SG_ BMS_DisChrg_Over_Curr : 12|1@1+ (1,0) [0|1] ""  BCM,HU
 SG_ BMS_LPDCDC_CutOFF : 6|1@1+ (1,0) [0|1] ""  BCM,HU
 SG_ BMS_Low_Temp_during_Drv_Err : 3|1@1+ (1,0) [0|1] ""  HU,BCM
 SG_ BMS_PDU_Lock_HW : 16|1@1+ (1,0) [0|1] ""  BCM,HU
 SG_ BMS_Pressure_Snsr_Err : 42|1@1+ (1,0) [0|1] ""  HU,BCM
 SG_ BMS_Gas_Snsr_Err : 41|1@1+ (1,0) [0|1] ""  HU,BCM
 SG_ BMS_LP_DCDC_Output_Shrt_Ckt : 40|1@1+ (1,0) [0|1] ""  HU,BCM
 SG_ BMS_Cell_Temp_Imbalance : 18|1@1+ (1,0) [0|1] ""  BCM,HU
 SG_ BMS_Insulation_Monitor_Err : 17|1@1+ (1,0) [0|1] ""  BCM,HU
 SG_ BMS_PDU_Fail : 33|1@1+ (1,0) [0|1] ""  HU,BCM
 SG_ BMS_Thermal_Runaway : 19|1@1+ (1,0) [0|1] ""  BCM,HU
 SG_ BMS_PreChrg_No_Load_Detected : 15|1@1+ (1,0) [0|1] ""  BCM,HU
 SG_ BMS_Short_Ckt_Detect_Err : 32|1@1+ (1,0) [0|1] ""  HU,BCM
 SG_ BMS_Over_Temp_Drv_Err : 11|1@1+ (1,0) [0|1] ""  HU,BCM
 SG_ BMS_Over_Temp_Drv_Warn_Info : 10|1@1+ (1,0) [0|1] ""  HU,BCM
 SG_ BMS_Over_Temp_Chrg_Err : 9|1@1+ (1,0) [0|1] ""  HU,BCM
 SG_ BMS_Over_Temp_Chrg_Warn_Info : 8|1@1+ (1,0) [0|1] ""  HU,BCM
 SG_ BMS_Under_Vlt_Err : 5|1@1+ (1,0) [0|1] ""  HU,BCM
 SG_ BMS_Under_Vlt_Warn_Info : 4|1@1+ (1,0) [0|1] ""  HU,BCM
 SG_ BMS_Over_Vlt_Chrg_Err : 7|1@1+ (1,0) [0|1] ""  HU,BCM
 SG_ BMS_PreChrg_Fail : 14|1@1+ (1,0) [0|1] ""  HU,BCM
 SG_ BMS_Over_Curr_Chrg_Err : 13|1@1+ (1,0) [0|1] ""  HU,BCM
 SG_ BMS_Curr_Snsr_Fail_Shrt_Ckt : 37|1@1+ (1,0) [0|1] ""  HU,BCM
 SG_ BMS_Curr_Snsr_Fail_Open_Ckt : 36|1@1+ (1,0) [0|1] ""  HU,BCM
 SG_ BMS_Low_Temp_during_Drv_Warn : 2|1@1+ (1,0) [0|1] ""  BCM,HU
 SG_ BMS_Low_Temp_during_Chrg_Err : 1|1@1+ (1,0) [0|1] ""  HU,BCM
 SG_ BMS_Low_Temp_Chrg_Warn_info : 0|1@1+ (1,0) [0|1] ""  HU,BCM

BO_ 1289 BMS_Flt_1: 8 BMS
 SG_ BMS_BattPack_Temp6_Snsr_Fail : 33|1@1+ (1,0) [0|1] ""  HU,BCM
 SG_ BMS_BattPack_Temp5_Snsr_Fail : 32|1@1+ (1,0) [0|1] ""  HU,BCM
 SG_ BMS_BattPack_Temp4_Snsr_Fail : 31|1@1+ (1,0) [0|1] ""  HU,BCM
 SG_ BMS_BattPack_Temp3_Snsr_Fail : 30|1@1+ (1,0) [0|1] ""  HU,BCM
 SG_ BMS_BattPack_Temp2_Snsr_Fail : 29|1@1+ (1,0) [0|1] ""  HU,BCM
 SG_ BMS_BattPack_Temp1_Snsr_Fail : 28|1@1+ (1,0) [0|1] ""  HU,BCM
 SG_ BMS_Vlt_Snsr_Fail_Cell28 : 27|1@1+ (1,0) [0|1] ""  HU,BCM
 SG_ BMS_Vlt_Snsr_Fail_Cell27 : 26|1@1+ (1,0) [0|1] ""  HU,BCM
 SG_ BMS_Vlt_Snsr_Fail_Cell26 : 25|1@1+ (1,0) [0|1] ""  HU,BCM
 SG_ BMS_Vlt_Snsr_Fail_Cell25 : 24|1@1+ (1,0) [0|1] ""  HU,BCM
 SG_ BMS_Vlt_Snsr_Fail_Cell24 : 23|1@1+ (1,0) [0|1] ""  HU,BCM
 SG_ BMS_Vlt_Snsr_Fail_Cell23 : 22|1@1+ (1,0) [0|1] ""  HU,BCM
 SG_ BMS_Vlt_Snsr_Fail_Cell22 : 21|1@1+ (1,0) [0|1] ""  HU,BCM
 SG_ BMS_Vlt_Snsr_Fail_Cell21 : 20|1@1+ (1,0) [0|1] ""  HU,BCM
 SG_ BMS_Vlt_Snsr_Fail_Cell20 : 19|1@1+ (1,0) [0|1] ""  HU,BCM
 SG_ BMS_Vlt_Snsr_Fail_Cell19 : 18|1@1+ (1,0) [0|1] ""  HU,BCM
 SG_ BMS_Vlt_Snsr_Fail_Cell18 : 17|1@1+ (1,0) [0|1] ""  HU,BCM
 SG_ BMS_Vlt_Snsr_Fail_Cell17 : 16|1@1+ (1,0) [0|1] ""  HU,BCM
 SG_ BMS_Vlt_Snsr_Fail_Cell16 : 15|1@1+ (1,0) [0|1] ""  HU,BCM
 SG_ BMS_Vlt_Snsr_Fail_Cell15 : 14|1@1+ (1,0) [0|1] ""  HU,BCM
 SG_ BMS_Vlt_Snsr_Fail_Cell14 : 13|1@1+ (1,0) [0|1] ""  HU,BCM
 SG_ BMS_Vlt_Snsr_Fail_Cell13 : 12|1@1+ (1,0) [0|1] ""  HU,BCM
 SG_ BMS_Vlt_Snsr_Fail_Cell12 : 11|1@1+ (1,0) [0|1] ""  HU,BCM
 SG_ BMS_Vlt_Snsr_Fail_Cell11 : 10|1@1+ (1,0) [0|1] ""  HU,BCM
 SG_ BMS_Vlt_Snsr_Fail_Cell10 : 9|1@1+ (1,0) [0|1] ""  HU,BCM
 SG_ BMS_Vlt_Snsr_Fail_Cell9 : 8|1@1+ (1,0) [0|1] ""  HU,BCM
 SG_ BMS_Vlt_Snsr_Fail_Cell8 : 7|1@1+ (1,0) [0|1] ""  HU,BCM
 SG_ BMS_Vlt_Snsr_Fail_Cell7 : 6|1@1+ (1,0) [0|1] ""  HU,BCM
 SG_ BMS_Vlt_Snsr_Fail_Cell6 : 5|1@1+ (1,0) [0|1] ""  HU,BCM
 SG_ BMS_Vlt_Snsr_Fail_Cell5 : 4|1@1+ (1,0) [0|1] ""  HU,BCM
 SG_ BMS_Vlt_Snsr_Fail_Cell4 : 3|1@1+ (1,0) [0|1] ""  HU,BCM
 SG_ BMS_Vlt_Snsr_Fail_Cell3 : 2|1@1+ (1,0) [0|1] ""  HU,BCM
 SG_ BMS_Vlt_Snsr_Fail_Cell2 : 1|1@1+ (1,0) [0|1] ""  HU,BCM
 SG_ BMS_Vlt_Snsr_Fail_Cell1 : 0|1@1+ (1,0) [0|1] ""  HU,BCM

BO_ 2030 BMS_Diagnostic_Response: 8 BMS
 SG_ BMS_Diag_Resp : 0|64@1+ (1,0) [0|1.84467440737096E+19] ""  BCM

BO_ 2029 OBC_Diagnostic_Response: 8 OBC
 SG_ OBC_Diag_Resp : 0|64@1+ (1,0) [0|1.84467440737096E+19] ""  BCM

BO_ 1295 OBC_HP_DCDC_Parameter1: 8 OBC
 SG_ HP_DCDC_Output_DC_Curr : 48|16@1+ (0.01,0) [0|655.35] "Amps"  BMS,BCM
 SG_ HP_DCDC_Output_DC_Vlt : 32|16@1+ (0.01,0) [0|655.35] "V"  BMS,BCM
 SG_ HP_DCDC_Input_DC_Curr : 16|16@1+ (0.01,0) [0|655.35] "Amps"  BMS,BCM
 SG_ HP_DCDC_Input_DC_Vlt : 0|16@1+ (0.01,0) [0|655.35] "V"  BMS,BCM

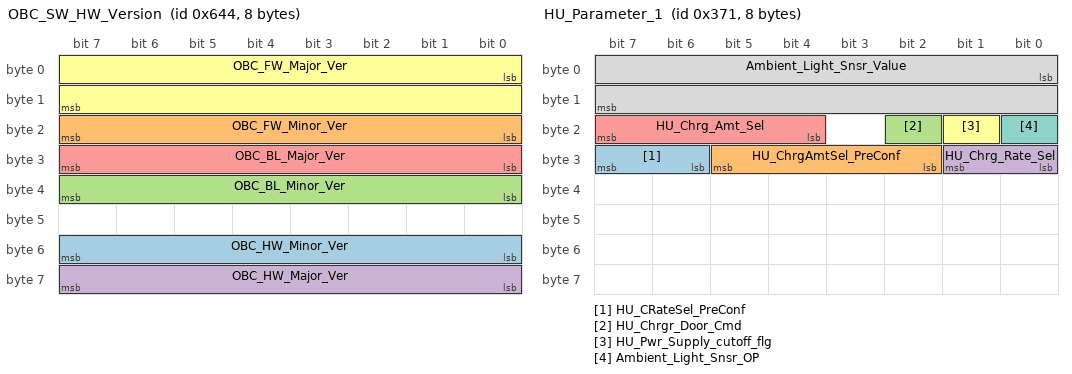
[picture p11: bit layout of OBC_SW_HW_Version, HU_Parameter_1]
BO_ 1604 OBC_SW_HW_Version: 8 OBC
 SG_ OBC_HW_Minor_Ver : 48|8@1+ (1,0) [0|255] ""  BCM
 SG_ OBC_FW_Minor_Ver : 16|8@1+ (1,0) [0|255] ""  BCM
 SG_ OBC_BL_Minor_Ver : 32|8@1+ (1,0) [0|255] ""  BCM
 SG_ OBC_HW_Major_Ver : 56|8@1+ (1,0) [0|255] ""  BCM
 SG_ OBC_BL_Major_Ver : 24|8@1+ (1,0) [0|4294967295] ""  BCM
 SG_ OBC_FW_Major_Ver : 0|16@1+ (1,0) [0|65535] ""  BCM

BO_ 2026 MCU_Diagnostic_Response: 8 MCU
 SG_ MCU_Diagnostic_Response : 0|64@1+ (1,0) [0|1.84467440737096E+19] ""  BCM

BO_ 881 HU_Parameter_1: 8 HU
 SG_ HU_CRateSel_PreConf : 30|2@1+ (1,0) [0|3] ""  BCM
 SG_ HU_ChrgAmtSel_PreConf : 26|4@1+ (1,0) [0|15] ""  BCM
 SG_ HU_Chrgr_Door_Cmd : 18|1@1+ (1,0) [0|1] ""  BCM
 SG_ HU_Chrg_Rate_Sel : 24|2@1+ (1,0) [0|3] ""  BCM
 SG_ HU_Chrg_Amt_Sel : 20|4@1+ (1,0) [0|15] ""  BCM
 SG_ HU_Pwr_Supply_cutoff_flg : 17|1@1+ (1,0) [0|1] ""  BCM
 SG_ Ambient_Light_Snsr_OP : 16|1@1+ (1,0) [0|1] ""  BCM
 SG_ Ambient_Light_Snsr_Value : 0|16@1+ (1,0) [0|65535] ""  BCM

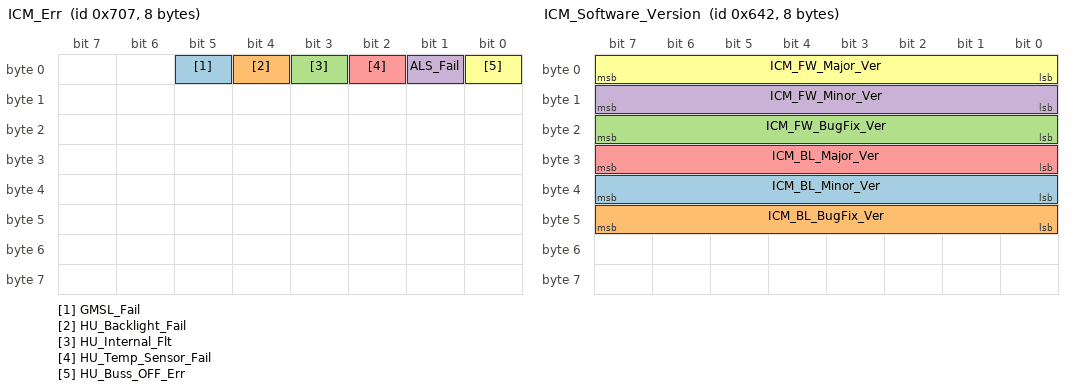
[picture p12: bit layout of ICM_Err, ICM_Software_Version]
BO_ 1799 ICM_Err: 8 HU
 SG_ GMSL_Fail : 5|1@1+ (1,0) [0|1] ""  BCM
 SG_ HU_Backlight_Fail : 4|1@1+ (1,0) [0|1] ""  BCM
 SG_ HU_Internal_Flt : 3|1@1+ (1,0) [0|1] ""  BCM
 SG_ ALS_Fail : 1|1@1+ (1,0) [0|1] ""  BCM
 SG_ HU_Temp_Sensor_Fail : 2|1@1+ (1,0) [0|1] ""  BCM
 SG_ HU_Buss_OFF_Err : 0|1@1+ (1,0) [0|1] ""  BCM

BO_ 2028 HU_Diagnostic_Response: 8 HU
 SG_ HU_Diag_Response : 0|64@1+ (1,0) [0|1.84467440737096E+19] ""  BCM

BO_ 1616 ICM_Digital_Input: 8 HU
 SG_ Main_Input_Supply : 8|16@1+ (1,0) [0|65535] "mV"  BCM
 SG_ Touch_Sts : 0|1@1+ (1,0) [0|1] ""  BCM

BO_ 1602 ICM_Software_Version: 8 HU
 SG_ ICM_BL_Minor_Ver : 32|8@1+ (1,0) [0|255] ""  BCM
 SG_ ICM_BL_BugFix_Ver : 40|8@1+ (1,0) [0|255] ""  BCM
 SG_ ICM_FW_BugFix_Ver : 16|8@1+ (1,0) [0|255] ""  BCM
 SG_ ICM_FW_Minor_Ver : 8|8@1+ (1,0) [0|255] ""  BCM
 SG_ ICM_BL_Major_Ver : 24|8@1+ (1,0) [0|255] ""  BCM
 SG_ ICM_FW_Major_Ver : 0|8@1+ (1,0) [0|255] ""  BCM

BO_ 1601 ICM_HW_Version_Info: 8 HU
 SG_ ICM_Hardware_Version : 0|64@1+ (1,0) [0|1.84467440737096E+19] ""  BCM

BO_ 268 VCU_Data: 8 BCM
 SG_ Chrgr_Door_Pwr_Supply : 57|1@1+ (1,0) [0|1] "" Vector__XXX
 SG_ Chrgr_Door_Sts : 56|1@1+ (1,0) [0|1] ""  HU
 SG_ Harsh_Brake_flg : 51|1@1+ (1,0) [0|1] ""  HU
 SG_ Harsh_Acc_Flg : 55|1@1+ (1,0) [0|1] ""  HU
 SG_ Licence_Plate_Power_Supply : 15|1@1+ (1,0) [0|1] "" Vector__XXX
 SG_ Wireless_Chrgr_Sts : 52|3@1+ (1,0) [0|6] "" Vector__XXX
 SG_ HU_Prep_Shutdown_flg : 39|1@1+ (1,0) [0|1] ""  HU
 SG_ ABS_Heartbeat_Fail_flg : 50|1@1+ (1,0) [0|1] "" Vector__XXX
 SG_ SSB_Illumination_Mode : 40|4@1+ (1,0) [0|15] "" Vector__XXX
 SG_ USB_Chrgr_Power_Supply : 38|1@1+ (1,0) [0|1] "" Vector__XXX
 SG_ Wireless_Chrgr_Power_Supply : 37|1@1+ (1,0) [0|1] "" Vector__XXX
 SG_ OBD_Power_Supply : 36|1@1+ (1,0) [0|1] "" Vector__XXX
 SG_ Mode_Down_Btn_Sts : 48|2@1+ (1,0) [0|3] ""  HU
 SG_ Mode_Up_Btn_Sts : 46|2@1+ (1,0) [0|3] ""  HU
 SG_ Aux_Btn_Sts : 44|2@1+ (1,0) [0|3] ""  HU
 SG_ ABS_IMU_Power_Supply : 14|1@1+ (1,0) [0|1] ""  HU
 SG_ Sleep_RTC_WakeUp_flg : 35|1@1+ (1,0) [0|1] "" Vector__XXX
 SG_ LIN_Comm_Fail_flg : 34|1@1+ (1,0) [0|1] "" Vector__XXX
 SG_ SPI_Comm_Fail_flg : 33|1@1+ (1,0) [0|1] "" Vector__XXX
 SG_ OBC_Hearbeat_Fail_flg : 32|1@1+ (1,0) [0|1] "" Vector__XXX
 SG_ MCU_Hearbeat_Fail_flg : 31|1@1+ (1,0) [0|1] ""  MCU
 SG_ BMS_Hearbeat_Fail_flg : 30|1@1+ (1,0) [0|1] ""  MCU
 SG_ Auto_Lock_Flg : 29|1@1+ (1,0) [0|1] ""  MCU
 SG_ Throttle_Response_CutOFF_Flag : 28|1@1+ (1,0) [0|1] ""  MCU
 SG_ Cruise_Availibilty_Status : 27|1@1+ (1,0) [0|1] "" Vector__XXX
 SG_ Drv_Enable : 26|1@1+ (1,0) [0|1] "" Vector__XXX
 SG_ Stop_Lamp_Sts : 25|1@1+ (1,0) [0|1] "" Vector__XXX
 SG_ Tail_Lamp_Sts : 24|1@1+ (1,0) [0|1] "" Vector__XXX
 SG_ Ignition_Sts : 23|1@1+ (1,0) [0|1] ""  HU,OBC,EHBL,BMS,MCU
 SG_ Veh_Authentication_Flag : 22|1@1+ (1,0) [0|1] ""  HU
 SG_ Position_Lamp_Power_Supply : 8|1@1+ (1,0) [0|1] "" Vector__XXX
 SG_ Tail_Lamp_Power_Supply : 21|1@1+ (1,0) [0|1] "" Vector__XXX
 SG_ Stop_Lamp_Power_Supply : 20|1@1+ (1,0) [0|1] "" Vector__XXX
 SG_ RSC_Power_Supply : 10|1@1+ (1,0) [0|1] "" Vector__XXX
 SG_ EHBL_Commands : 16|3@1+ (1,0) [0|7] ""  EHBL
 SG_ EHBL_Power_Supply : 19|1@1+ (1,0) [0|1] ""  EHBL
 SG_ SOM_Power_Supply : 13|1@1+ (1,0) [0|1] "" Vector__XXX
 SG_ Speaker_Power_Supply : 12|1@1+ (1,0) [0|1] "" Vector__XXX
 SG_ Horn_Power_Supply : 11|1@1+ (1,0) [0|1] "" Vector__XXX
 SG_ LSC_Power_Supply : 9|1@1+ (1,0) [0|1] "" Vector__XXX
 SG_ Low_Beam_Power_Supply : 7|1@1+ (1,0) [0|1] "" Vector__XXX
 SG_ High_Beam_Power_Supply : 6|1@1+ (1,0) [0|1] "" Vector__XXX
 SG_ Right_Indicator_Power_Supply : 5|1@1+ (1,0) [0|1] ""  HU
 SG_ Left_Indicator_Power_Supply : 4|1@1+ (1,0) [0|1] ""  HU
 SG_ HU_Power_Supply : 3|1@1+ (1,0) [0|1] ""  HU
 SG_ MCU_Power_Supply : 2|1@1+ (1,0) [0|1] "" Vector__XXX
 SG_ Chrgr_Plugin : 0|2@1+ (1,0) [0|3] ""  BMS,HU,EHBL,MCU

BO_ 2019 EHBL_Diagnostic_Request: 8 BCM
 SG_ EHBL_Diag_Request : 0|64@1+ (1,0) [0|1.84467440737096E+19] ""  EHBL

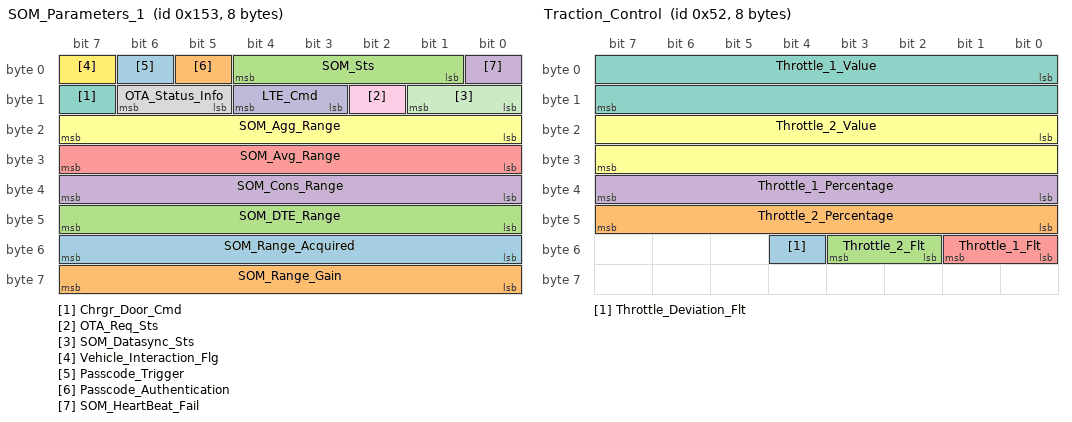
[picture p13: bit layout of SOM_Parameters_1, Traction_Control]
BO_ 339 SOM_Parameters_1: 8 BCM
 SG_ SOM_Range_Acquired : 48|8@1+ (1,0) [0|255] "km"  HU
 SG_ SOM_Range_Gain : 56|8@1+ (1,0) [0|255] "km"  HU
 SG_ SOM_DTE_Range : 40|8@1+ (1,0) [0|255] "km"  HU
 SG_ SOM_Cons_Range : 32|8@1+ (1,0) [0|255] "km"  HU
 SG_ SOM_Avg_Range : 24|8@1+ (1,0) [0|255] "km"  HU
 SG_ SOM_Agg_Range : 16|8@1+ (1,0) [0|255] "km"  HU
 SG_ Chrgr_Door_Cmd : 15|1@1+ (1,0) [0|1] "" Vector__XXX
 SG_ OTA_Status_Info : 13|2@1+ (1,0) [0|3] "" Vector__XXX
 SG_ OTA_Req_Sts : 10|1@1+ (1,0) [0|1] "" Vector__XXX
 SG_ LTE_Cmd : 11|2@1+ (1,0) [0|3] "" Vector__XXX
 SG_ SOM_Datasync_Sts : 8|2@1+ (1,0) [0|3] "" Vector__XXX
 SG_ Vehicle_Interaction_Flg : 7|1@1+ (1,0) [0|1] "" Vector__XXX
 SG_ Passcode_Trigger : 6|1@1+ (1,0) [0|1] "" Vector__XXX
 SG_ Passcode_Authentication : 5|1@1+ (1,0) [0|1] "" Vector__XXX
 SG_ SOM_Sts : 1|4@1+ (1,0) [0|15] ""  HU
 SG_ SOM_HeartBeat_Fail : 0|1@1+ (1,0) [0|1] ""  HU

BO_ 82 Traction_Control: 8 BCM
 SG_ Throttle_Deviation_Flt : 52|1@1+ (1,0) [0|1] "" Vector__XXX
 SG_ Throttle_2_Percentage : 40|8@1- (1,0) [-128|127] "%" Vector__XXX
 SG_ Throttle_2_Flt : 50|2@1+ (1,0) [0|3] ""  ABS
 SG_ Throttle_1_Percentage : 32|8@1- (1,0) [-128|127] "%" Vector__XXX
 SG_ Throttle_1_Flt : 48|2@1+ (1,0) [0|3] ""  ABS
 SG_ Throttle_2_Value : 16|16@1+ (1,0) [0|10000] "mV"  MCU
 SG_ Throttle_1_Value : 0|16@1+ (1,0) [0|10000] "mV"  MCU

BO_ 2022 BMS_Diagnostic_Request: 8 BCM
 SG_ BMS_Diag_Request : 0|64@1+ (1,0) [0|1.84467440737096E+19] ""  BMS

BO_ 2021 OBC_Diagnostic_Request: 8 BCM
 SG_ OBC_Diag_Request : 0|64@1+ (1,0) [0|1.84467440737096E+19] ""  OBC

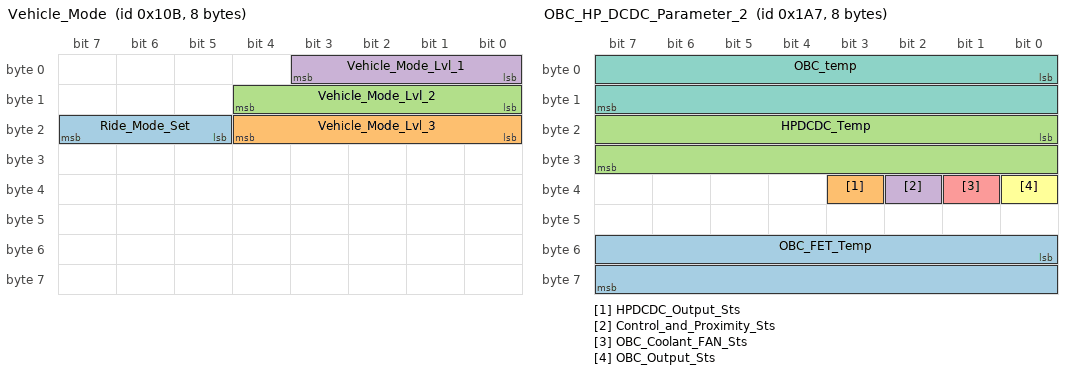
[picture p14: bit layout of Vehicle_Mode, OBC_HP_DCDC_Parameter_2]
BO_ 267 Vehicle_Mode: 8 BCM
 SG_ Ride_Mode_Set : 21|3@1+ (1,0) [0|7] ""  HU
 SG_ Vehicle_Mode_Lvl_3 : 16|5@1+ (1,0) [0|31] ""  HU,ABS,BMS,MCU
 SG_ Vehicle_Mode_Lvl_2 : 8|5@1+ (1,0) [0|31] ""  HU,MCU,OBC,BMS
 SG_ Vehicle_Mode_Lvl_1 : 0|4@1+ (1,0) [0|15] ""  HU,MCU,OBC,BMS

BO_ 2018 MCU_Diagnostic_Request: 8 BCM
 SG_ MCU_Diag_Request : 0|64@1+ (1,0) [0|1.84467440737096E+19] ""  MCU

BO_ 266 Vehicle_Functions: 8 BCM
 SG_ OTA_Resp_Sts : 58|3@1+ (1,0) [0|7] ""  HU
 SG_ Mic_Sts : 61|2@1+ (1,0) [0|3] ""  HU
 SG_ Cruise_btn_Sts : 56|2@1+ (1,0) [0|1] "" Vector__XXX
 SG_ Ok_Sts : 50|2@1+ (1,0) [0|3] ""  HU
 SG_ Home_Sts : 48|2@1+ (1,0) [0|3] ""  HU
 SG_ Down_Joy_Stick_Sts : 46|2@1+ (1,0) [0|3] ""  HU
 SG_ Up_Joy_Stick_Sts : 44|2@1+ (1,0) [0|3] ""  HU
 SG_ Right_Joy_Stick_Sts : 42|2@1+ (1,0) [0|3] ""  HU
 SG_ Left_Joy_Stick_Sts : 40|2@1+ (1,0) [0|3] ""  HU
 SG_ True_Vehicle_speed_kmph : 24|16@1+ (0.1,0) [0|6553.5] ""  BMS,MCU,EHBL
 SG_ Cruise_Max_speed_kmph : 16|8@1+ (1,0) [0|255] "kmph" Vector__XXX
 SG_ Start_Stop_Button_Sts : 6|2@1+ (1,0) [0|3] "" Vector__XXX
 SG_ SOS_Btn : 1|1@1+ (1,0) [0|1] "" Vector__XXX
 SG_ Start_Stop_Btn : 0|1@1+ (1,0) [0|1] ""  ABS
 SG_ Cruise_Min_speed_kmph : 8|8@1+ (1,0) [0|255] "kmph" Vector__XXX
 SG_ Hill_Hold_Command : 52|3@1+ (1,0) [0|7] ""  MCU,ABS
 SG_ Cruise_Control_Req : 2|3@1+ (1,0) [0|7] ""  MCU

BO_ 1627 IMU_Data_Z: 8 BCM
 SG_ Yaw : 48|16@1+ (1,0) [0|360] "deg" Vector__XXX
 SG_ Magnetometer_Zaxis : 32|16@1- (1,0) [-32768|32767] "mG" Vector__XXX
 SG_ Gyroscope_Zaxis : 16|16@1- (1,0) [-32768|32767] "mdps" Vector__XXX
 SG_ Accelerometer_Zaxis : 0|16@1- (1,0) [-32768|32767] "mg" Vector__XXX

BO_ 1611 IMU_Data_Y: 8 BCM
 SG_ Pitch : 48|16@1- (1,0) [-180|180] "deg"  MCU
 SG_ Magnetometer_Yaxis : 32|16@1- (1,0) [-32768|32767] "mG" Vector__XXX
 SG_ Gyroscope_Yaxis : 16|16@1- (1,0) [-32768|32767] "mdps" Vector__XXX
 SG_ Accelerometer_Yaxis : 0|16@1- (1,0) [-32768|32767] "mg" Vector__XXX

BO_ 1579 IMU_Data_X: 8 BCM
 SG_ Roll : 48|16@1- (1,0) [-180|180] "deg" Vector__XXX
 SG_ Magnetometer_Xaxis : 32|16@1- (1,0) [-32768|32767] "mG" Vector__XXX
 SG_ Gyroscope_Xaxis : 16|16@1- (1,0) [-32768|32767] "mdps" Vector__XXX
 SG_ Accelerometer_Xaxis : 0|16@1- (1,0) [-32768|32767] "mg" Vector__XXX

BO_ 865 Display_info: 8 BCM
 SG_ VCU_CRate_Sel_PreConf : 56|2@1+ (1,0) [0|3] ""  BMS
 SG_ Tow_Detection_Flg : 60|2@1+ (1,0) [0|3] ""  HU
 SG_ Crash_Detection_Flg : 58|2@1+ (1,0) [0|3] ""  HU
 SG_ Indicators_Fault : 28|4@1+ (1,0) [0|15] ""  HU
 SG_ Range_Acquired : 0|8@1+ (1,0) [0|255] "km"  HU
 SG_ VCU_Chrg_Rate_Sel : 62|2@1+ (1,0) [0|3] ""  BMS
 SG_ VCU_Chrg_Amt_Sel : 8|4@1+ (1,0) [0|15] ""  BMS
 SG_ VCU_ChrgAmtSel_PreConf : 12|4@1+ (1,0) [0|15] ""  BMS
 SG_ Regen_Availibilty_Flg : 48|1@1+ (1,0) [0|1] "" Vector__XXX
 SG_ Hill_Hold_TTL : 54|2@1+ (1,0) [0|3] ""  HU
 SG_ Regen_TTL : 52|2@1+ (1,0) [0|3] "" Vector__XXX
 SG_ Cruise_Control_TTL : 49|3@1+ (1,0) [0|7] ""  HU
 SG_ Cruise_Set_Speed : 40|8@1+ (1,0) [0|255] "kmph"  HU,MCU
 SG_ Display_Vehicle_Speed : 32|8@1+ (1,0) [0|255] "kmph"  MCU,HU
 SG_ Position_Lamp_TTL : 19|1@1+ (1,0) [0|1] ""  HU
 SG_ FrontLight_TTL : 24|4@1+ (1,0) [0|15] ""  HU
 SG_ Indicators_TTL : 20|4@1+ (1,0) [0|15] ""  HU
 SG_ Side_Stand_Sts : 16|3@1+ (1,0) [0|7] ""  HU

BO_ 2020 HU_Diagnostic_Request: 8 BCM
 SG_ HU_Diag_Request : 0|64@1+ (1,0) [0|1.84467440737096E+19] ""  HU

BO_ 423 OBC_HP_DCDC_Parameter_2: 8 OBC
 SG_ OBC_FET_Temp : 48|16@1+ (0.01,-50) [-50|600] "DegC"  BCM
 SG_ HPDCDC_Output_Sts : 35|1@1+ (1,0) [0|1] ""  BCM
 SG_ HPDCDC_Temp : 16|16@1+ (0.01,-50) [-50|600] "degC"  BCM
 SG_ Control_and_Proximity_Sts : 34|1@1+ (1,0) [0|1] ""  BCM
 SG_ OBC_Coolant_FAN_Sts : 33|1@1+ (1,0) [0|1] ""  BCM
 SG_ OBC_Output_Sts : 32|1@1+ (1,0) [0|1] ""  BCM
 SG_ OBC_temp : 0|16@1+ (0.01,-50) [-50|600] "degC"  BCM

BO_ 415 Chrgr_Parameter_1: 8 OBC
 SG_ Chrgr_Output_DC_Curr : 48|16@1+ (0.01,0) [0|655.35] "A"  BMS,BCM
 SG_ Chrgr_Output_DC_Vlt : 32|16@1+ (0.01,0) [0|655.35] "V"  BMS,BCM
 SG_ Chrgr_Input_AC_Curr : 16|16@1+ (0.01,0) [0|655.35] "A"  BMS,BCM
 SG_ Chrgr_Input_AC_Vlt : 0|16@1+ (0.01,0) [0|655.35] "V"  BMS,BCM

BO_ 1294 Chrgr_FLT_Info: 8 OBC
 SG_ OBC_Output_Under_Vlt_Flt : 12|1@1+ (1,0) [0|1] ""  HU,BMS,BCM
 SG_ DCDC_Output_Over_Vlt_Flt : 13|1@1+ (1,0) [0|1] ""  HU,BMS,BCM
 SG_ DCDC_Temp_Snsr_Fail : 20|1@1+ (1,0) [0|1] ""  HU,BMS,BCM
 SG_ DCDC_Output_Shrt_Ckt : 24|1@1+ (1,0) [0|1] ""  HU,BMS,BCM
 SG_ DCDC_Output_Over_Curr : 17|1@1+ (1,0) [0|1] ""  HU,BMS,BCM
 SG_ DCDC_Output_Open_Ckt : 23|1@1+ (1,0) [0|1] ""  HU,BMS,BCM
 SG_ DCDC_Low_Temp : 19|1@1+ (1,0) [0|1] ""  HU,BCM,BMS
 SG_ DCDC_Input_Under_Vlt : 15|1@1+ (1,0) [0|1] ""  HU,BMS,BCM
 SG_ DCDC_Input_Over_Vlt : 14|1@1+ (1,0) [0|1] ""  HU,BMS,BCM
 SG_ DCDC_Input_Over_Curr : 16|1@1+ (1,0) [0|1] ""  HU,BMS,BCM
 SG_ DCDC_High_Temp : 18|1@1+ (1,0) [0|1] ""  HU,BMS,BCM
 SG_ DCDC_Output_Under_Vlt_Flt : 25|1@1+ (1,0) [0|1] ""  HU,BMS,BCM
 SG_ DC_DC_Curr_Sensing_Fail : 21|1@1+ (1,0) [0|1] ""  HU,BMS,BCM
 SG_ DCDC_Contactor_or_Relay_Fail : 22|1@1+ (1,0) [0|1] ""  HU,BMS,BCM
 SG_ OBC_Output_Over_Vlt_Flt : 11|1@1+ (1,0) [0|1] ""  HU,BMS,BCM
 SG_ OBC_Output_Shrt_Ckt_Fail : 10|1@1+ (1,0) [0|1] ""  HU,BMS,BCM
 SG_ OBC_Output_Open_Ckt : 9|1@1+ (1,0) [0|1] ""  HU,BMS,BCM
 SG_ OBC_Contactor_or_Relay_Fail : 8|1@1+ (1,0) [0|1] ""  HU,BMS,BCM
 SG_ OBC_Curr_Sensing_Fail : 7|1@1+ (1,0) [0|1] ""  HU,BMS,BCM
 SG_ OBC_Temp_Snsr_Fail : 6|1@1+ (1,0) [0|1] ""  HU,BMS,BCM
 SG_ OBC_Low_temp : 5|1@1+ (1,0) [0|1] ""  HU,BMS,BCM
 SG_ OBC_High_Temp : 4|1@1+ (1,0) [0|1] ""  HU,BMS,BCM
 SG_ OBC_Output_Over_Curr : 3|1@1+ (1,0) [0|1] ""  HU,BMS,BCM
 SG_ OBC_Input_Over_Curr : 2|1@1+ (1,0) [0|1] ""  HU,BMS,BCM
 SG_ OBC_Input_AC_under_Vlt : 1|1@1+ (1,0) [0|1] ""  HU,BMS,BCM
 SG_ OBC_Input_AC_Over_Vlt : 0|1@1+ (1,0) [0|1] ""  HU,BMS,BCM

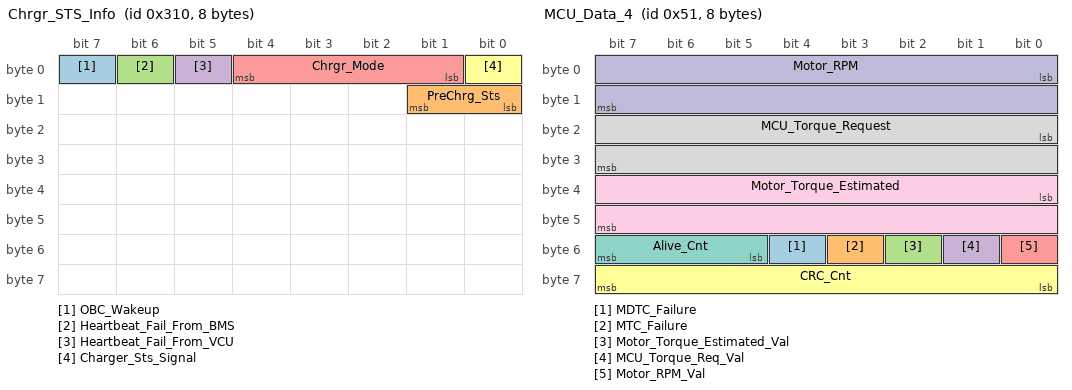
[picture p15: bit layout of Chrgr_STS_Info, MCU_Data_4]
BO_ 784 Chrgr_STS_Info: 8 OBC
 SG_ OBC_Wakeup : 7|1@1+ (1,0) [0|1] ""  BMS,HU,BCM
 SG_ PreChrg_Sts : 8|2@1+ (1,0) [0|3] ""  BCM
 SG_ Heartbeat_Fail_From_BMS : 6|1@1+ (1,0) [0|1] ""  BCM
 SG_ Heartbeat_Fail_From_VCU : 5|1@1+ (1,0) [0|1] ""  BCM
 SG_ Chrgr_Mode : 1|4@1+ (1,0) [0|15] ""  BMS,BCM
 SG_ Charger_Sts_Signal : 0|1@1+ (1,0) [0|1] ""  BCM

BO_ 81 MCU_Data_4: 8 MCU
 SG_ MDTC_Failure : 52|1@1+ (1,0) [0|1] ""  BCM,ABS
 SG_ MTC_Failure : 51|1@1+ (1,0) [0|1] ""  BCM,ABS
 SG_ Motor_Torque_Estimated_Val : 50|1@1+ (1,0) [0|1] ""  BCM,ABS
 SG_ MCU_Torque_Req_Val : 49|1@1+ (1,0) [0|1] ""  ABS,BCM
 SG_ Motor_RPM_Val : 48|1@1+ (1,0) [0|1] ""  BCM,ABS
 SG_ CRC_Cnt : 56|8@1+ (1,0) [0|255] ""  BCM,ABS
 SG_ Alive_Cnt : 53|3@1+ (1,0) [0|7] ""  BCM,ABS
 SG_ MCU_Torque_Request : 16|16@1- (0.01,0) [-327|326] ""  BCM,ABS
 SG_ Motor_Torque_Estimated : 32|16@1- (0.01,0) [-327|326] "Nm"  BCM,ABS,HU
 SG_ Motor_RPM : 0|16@1- (1,0) [-32768|32767] "rpm"  ABS,EHBL,BCM

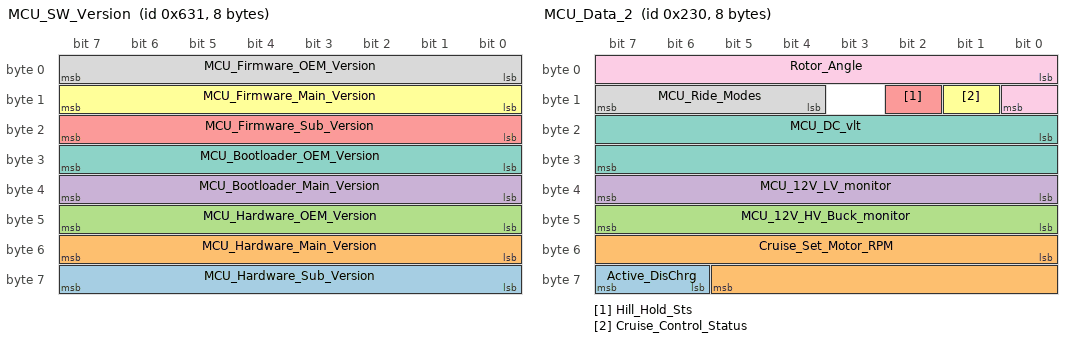
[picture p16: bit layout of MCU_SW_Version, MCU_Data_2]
BO_ 1585 MCU_SW_Version: 8 MCU
 SG_ MCU_Hardware_Sub_Version : 56|8@1+ (1,0) [0|255] ""  BCM
 SG_ MCU_Hardware_Main_Version : 48|8@1+ (1,0) [0|255] ""  BCM
 SG_ MCU_Hardware_OEM_Version : 40|8@1+ (1,0) [0|255] ""  BCM
 SG_ MCU_Bootloader_Main_Version : 32|8@1+ (1,0) [0|255] ""  BCM
 SG_ MCU_Firmware_Sub_Version : 16|8@1+ (1,0) [0|255] ""  BCM
 SG_ MCU_Firmware_Main_Version : 8|8@1+ (1,0) [0|255] ""  BCM
 SG_ MCU_Bootloader_OEM_Version : 24|8@1+ (1,0) [0|255] ""  BCM
 SG_ MCU_Firmware_OEM_Version : 0|8@1+ (1,0) [0|255] ""  BCM

BO_ 833 MCU_FLT_Data: 8 MCU
 SG_ Bus_OFF_Err : 63|1@1+ (1,0) [0|1] ""  BCM,HU
 SG_ MCU_GD_Fail_Sts : 62|1@1+ (1,0) [0|1] ""  BCM,HU
 SG_ MCU_OnAxis_Fail_Sts : 61|1@1+ (1,0) [0|1] ""  BCM,HU
 SG_ MCU_SBC_G3_Flt : 60|1@1+ (1,0) [0|1] ""  BCM,HU
 SG_ MCU_GateDriver_G3_Flt : 59|1@1+ (1,0) [0|1] ""  BCM,HU
 SG_ MCU_GD_Int_b_Flt : 58|1@1+ (1,0) [0|1] ""  BCM,HU
 SG_ MCU_Unintended_Trq_Flt : 57|1@1+ (1,0) [0|1] ""  BCM,HU
 SG_ MCU_Phase_Curr_Sum_Flt : 56|1@1+ (1,0) [0|1] ""  BCM,HU
 SG_ MCU_Flt_On_Axis_G3_Failure : 54|1@1+ (1,0) [0|1] ""  BCM,HU
 SG_ MCU_Dio_Phase_Over_Curr_Sts : 55|1@1+ (1,0) [0|1] ""  BCM,HU
 SG_ MCU_SBC_Fail_Sts : 39|1@1+ (1,0) [0|1] ""  BCM,HU
 SG_ MCU_Dio_DC_Over_Curr_Flt : 32|1@1+ (1,0) [0|1] ""  HU,BCM
 SG_ MCU_MOSFET_Low_Temp_Flt : 31|1@1+ (1,0) [0|1] ""  BCM,HU
 SG_ Mcu_Flt_NVM_Vlt_Notstable : 47|1@1+ (1,0) [0|1] ""  BCM,HU
 SG_ MOSFET_over_Temp_Err : 53|1@1+ (1,0) [0|1] ""  HU,BCM
 SG_ MCU_over_Temp_Err : 52|1@1+ (1,0) [0|1] ""  HU,BCM
 SG_ Motor_over_Temp_Err : 51|1@1+ (1,0) [0|1] ""  HU,BCM
 SG_ MOSFET_over_Temp_Warn : 50|1@1+ (1,0) [0|1] ""  HU,BCM
 SG_ MCU_NVM_Vlt_ChkSm_Mismatch : 49|1@1+ (1,0) [0|1] ""  HU,BCM
 SG_ Mcu_Flt_PhaseOffsetErr : 48|1@1+ (1,0) [0|1] ""  BCM,HU
 SG_ Mcu_Flt_BuckConverter_UV : 46|1@1+ (1,0) [0|1] ""  BCM,HU
 SG_ Mcu_Flt_BuckConverter_STG : 45|1@1+ (1,0) [0|1] ""  BCM,HU
 SG_ Mcu_Flt_BuckConverter_STB : 44|1@1+ (1,0) [0|1] ""  BCM,HU
 SG_ Mcu_Flt_BuckConverter_OV : 43|1@1+ (1,0) [0|1] ""  BCM,HU
 SG_ LV_supplyUnderVlt : 22|1@1+ (1,0) [0|1] ""  HU,BCM
 SG_ LV_supplyOverVlt : 21|1@1+ (1,0) [0|1] ""  HU,BCM
 SG_ Throttle_ideal_per_Err : 42|1@1+ (1,0) [0|1] ""  HU,BCM
 SG_ MCU_Flt_MOSFET_STB : 41|1@1+ (1,0) [0|1] ""  HU,BCM
 SG_ MCU_Flt_MOSFET_STG : 40|1@1+ (1,0) [0|1] ""  HU,BCM
 SG_ Mcu_Flt_Rotor_Stall : 38|1@1+ (1,0) [0|1] ""  HU,BCM
 SG_ Mcu_Flt_BoardTemp_Low : 37|1@1+ (1,0) [0|1] ""  HU,BCM
 SG_ Mcu_Flt_MachineTemp_Low : 36|1@1+ (1,0) [0|1] ""  HU,BCM
 SG_ MCU_dio_phase_ctrl_sts : 35|1@1+ (1,0) [0|1] ""  HU,BCM
 SG_ MCU_dio_over_curr_status : 34|1@1+ (1,0) [0|1] ""  HU,BCM
 SG_ MCU_dio_over_volt_sts : 33|1@1+ (1,0) [0|1] ""  HU,BCM
 SG_ Mcu_Flt_DCCurrentSnsrSTB : 30|1@1+ (1,0) [0|1] ""  HU,BCM
 SG_ Mcu_Flt_DCCurrentSnsrSTG : 29|1@1+ (1,0) [0|1] ""  HU,BCM
 SG_ MCU_Flt_MachineTempSnsrSTG : 28|1@1+ (1,0) [0|1] ""  HU,BCM
 SG_ MCU_Flt_MachineTempSnsrSTB : 27|1@1+ (1,0) [0|1] ""  HU,BCM
 SG_ Mcu_Flt_BphaseSTB : 26|1@1+ (1,0) [0|1] ""  HU,BCM
 SG_ Mcu_Flt_BphaseSTG : 25|1@1+ (1,0) [0|1] ""  HU,BCM
 SG_ Mcu_Flt_YphaseSTB : 24|1@1+ (1,0) [0|1] ""  HU,BCM
 SG_ Mcu_Flt_YphaseSTG : 23|1@1+ (1,0) [0|1] ""  HU,BCM
 SG_ Loss_of_VCU_Msg : 20|1@1+ (1,0) [0|1] ""  HU,BCM
 SG_ Mcu_Flt_RphaseSTB : 19|1@1+ (1,0) [0|1] ""  HU,BCM
 SG_ Mcu_Flt_RphaseSTG : 18|1@1+ (1,0) [0|1] ""  HU,BCM
 SG_ Mcu_Flt_BoardTempSnsrSTB : 17|1@1+ (1,0) [0|1] ""  HU,BCM
 SG_ Mcu_Flt_BoardTempSnsrSTG : 16|1@1+ (1,0) [0|1] ""  HU,BCM
 SG_ MCU_Flt_KL30_Snsr_STB : 15|1@1+ (1,0) [0|1] ""  HU,BCM
 SG_ MCU_Flt_KL30_Snsr_STG : 14|1@1+ (1,0) [0|1] ""  HU,BCM
 SG_ Mcu_Flt_DCBus_VoltgeSnsr_STB : 13|1@1+ (1,0) [0|1] ""  HU,BCM
 SG_ Mcu_Flt_DCBus_VltSnsr_STG : 12|1@1+ (1,0) [0|1] ""  HU,BCM
 SG_ MCU_Over_speed_Flt : 11|1@1+ (1,0) [0|1] ""  HU,BCM
 SG_ DCbus_OverCurr : 10|1@1+ (1,0) [0|1] ""  HU,BCM
 SG_ DCbus_OverVlt : 9|1@1+ (1,0) [0|1] ""  HU,BCM
 SG_ DCbus_UnderVlt : 8|1@1+ (1,0) [0|1] ""  HU,BCM
 SG_ Encoder_Fail : 7|1@1+ (1,0) [0|1] ""  HU,BCM
 SG_ MCU_Unintended_Direction : 6|1@1+ (1,0) [0|1] ""  HU,BCM
 SG_ Motor_over_temp_warn : 5|1@1+ (1,0) [0|1] ""  HU,BCM
 SG_ MCU_over_temp_warn : 4|1@1+ (1,0) [0|1] ""  HU,BCM
 SG_ Mcu_Flt_Wrong_Offset_Flt : 3|1@1+ (1,0) [0|1] ""  HU,BCM
 SG_ Motor_OC_protect_W_phase : 2|1@1+ (1,0) [0|1] ""  HU,BCM
 SG_ Motor_OC_protect_V_phase : 1|1@1+ (1,0) [0|1] ""  HU,BCM
 SG_ Motor_OC_protect_U_phase : 0|1@1+ (1,0) [0|1] ""  HU,BCM

BO_ 560 MCU_Data_2: 8 MCU
 SG_ Active_DisChrg : 62|2@1+ (1,0) [0|3] ""  BCM
 SG_ Cruise_Set_Motor_RPM : 48|14@1+ (1,0) [0|16383] "RPM"  BCM
 SG_ MCU_12V_HV_Buck_monitor : 40|8@1+ (0.1,0) [0|25.5] ""  BCM
 SG_ MCU_12V_LV_monitor : 32|8@1+ (0.1,0) [0|25.5] ""  BCM
 SG_ Hill_Hold_Sts : 10|1@1+ (1,0) [0|1] ""  BCM
 SG_ Cruise_Control_Status : 9|1@1+ (1,0) [0|1] ""  BCM
 SG_ MCU_DC_vlt : 16|16@1+ (0.01,0) [0|655.35] "V"  BCM
 SG_ MCU_Ride_Modes : 12|4@1+ (1,0) [0|15] ""  HU,BCM
 SG_ Rotor_Angle : 0|9@1+ (1,0) [0|511] ""  BCM

BO_ 566 MCU_Data_1: 8 MCU
 SG_ Rotor_theta : 48|16@1+ (0.001,0) [0|65.5] "Radian"  BCM
 SG_ Motor_Temp_1 : 32|16@1+ (0.01,-55) [-55|600.35] "degC"  BMS,BCM
 SG_ MCU_Temp : 16|16@1+ (0.01,-55) [-55|600.35] "degC"  BMS,BCM
 SG_ MCU_DC_Curr : 0|16@1+ (0.1,-1000) [-1000|5553.5] "A"  BCM

BO_ 1288 BMS_Cell_Sts: 8 BMS
 SG_ BAL_Sts : 28|1@1+ (1,0) [0|1] ""  BCM
 SG_ BMS_BAL_Sts_Batt_Cell_19 : 18|1@1+ (1,0) [0|1] ""  BCM
 SG_ BMS_Cell_Max_Vlt : 48|16@1+ (0.001,0) [0|65.535] "V"  BCM
 SG_ BMS_Cell_Min_Vlt : 32|16@1+ (0.001,0) [0|65.535] "V"  BCM
 SG_ BMS_BAL_Sts_Batt_Cell_9 : 8|1@1+ (1,0) [0|1] ""  BCM
 SG_ BMS_BAL_Sts_Batt_Cell_8 : 7|1@1+ (1,0) [0|1] ""  BCM
 SG_ BMS_BAL_Sts_Batt_Cell_7 : 6|1@1+ (1,0) [0|1] ""  BCM
 SG_ BMS_BAL_Sts_Batt_Cell_6 : 5|1@1+ (1,0) [0|1] ""  BCM
 SG_ BMS_BAL_Sts_Batt_Cell_5 : 4|1@1+ (1,0) [0|1] ""  BCM
 SG_ BMS_BAL_Sts_Batt_Cell_4 : 3|1@1+ (1,0) [0|1] ""  BCM
 SG_ BMS_BAL_Sts_Batt_Cell_3 : 2|1@1+ (1,0) [0|1] ""  BCM
 SG_ BMS_BAL_Sts_Batt_Cell_28 : 27|1@1+ (1,0) [0|1] ""  BCM
 SG_ BMS_BAL_Sts_Batt_Cell_27 : 26|1@1+ (1,0) [0|1] ""  BCM
 SG_ BMS_BAL_Sts_Batt_Cell_26 : 25|1@1+ (1,0) [0|1] ""  BCM
 SG_ BMS_BAL_Sts_Batt_Cell_25 : 24|1@1+ (1,0) [0|1] ""  BCM
 SG_ BMS_BAL_Sts_Batt_Cell_24 : 23|1@1+ (1,0) [0|1] ""  BCM
 SG_ BMS_BAL_Sts_Batt_Cell_23 : 22|1@1+ (1,0) [0|1] ""  BCM
 SG_ BMS_BAL_Sts_Batt_Cell_22 : 21|1@1+ (1,0) [0|1] ""  BCM
 SG_ BMS_BAL_Sts_Batt_Cell_21 : 20|1@1+ (1,0) [0|1] ""  BCM
 SG_ BMS_BAL_Sts_Batt_Cell_20 : 19|1@1+ (1,0) [0|1] ""  BCM
 SG_ BMS_BAL_Sts_Batt_Cell_2 : 1|1@1+ (1,0) [0|1] ""  BCM
 SG_ BMS_BAL_Sts_Batt_Cell_18 : 17|1@1+ (1,0) [0|1] ""  BCM
 SG_ BMS_BAL_Sts_Batt_Cell_17 : 16|1@1+ (1,0) [0|1] ""  BCM
 SG_ BMS_BAL_Sts_Batt_Cell_16 : 15|1@1+ (1,0) [0|1] ""  BCM
 SG_ BMS_BAL_Sts_Batt_Cell_15 : 14|1@1+ (1,0) [0|1] ""  BCM
 SG_ BMS_BAL_Sts_Batt_Cell_14 : 13|1@1+ (1,0) [0|1] ""  BCM
 SG_ BMS_BAL_Sts_Batt_Cell_13 : 12|1@1+ (1,0) [0|1] ""  BCM
 SG_ BMS_BAL_Sts_Batt_Cell_12 : 11|1@1+ (1,0) [0|1] ""  BCM
 SG_ BMS_BAL_Sts_Batt_Cell_11 : 10|1@1+ (1,0) [0|1] ""  BCM
 SG_ BMS_BAL_Sts_Batt_Cell_10 : 9|1@1+ (1,0) [0|1] ""  BCM
 SG_ BMS_BAL_Sts_Batt_Cell_1 : 0|1@1+ (1,0) [0|1] ""  BCM

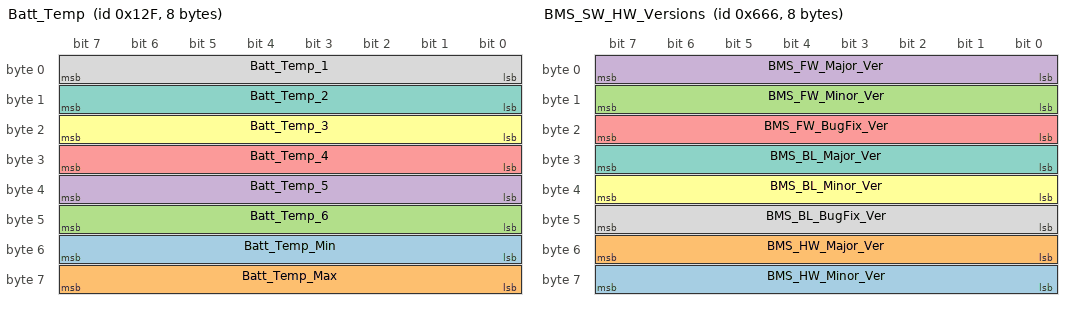
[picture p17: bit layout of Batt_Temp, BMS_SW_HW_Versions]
BO_ 303 Batt_Temp: 8 BMS
 SG_ Batt_Temp_Min : 48|8@1+ (0.5,-30) [-30|97.5] "degC"  BCM
 SG_ Batt_Temp_Max : 56|8@1+ (0.5,-30) [-30|97.5] "degC"  MCU,BCM
 SG_ Batt_Temp_6 : 40|8@1+ (0.5,-30) [-30|97.5] "degC"  BCM
 SG_ Batt_Temp_5 : 32|8@1+ (0.5,-30) [-30|97.5] "degC"  BCM
 SG_ Batt_Temp_4 : 24|8@1+ (0.5,-30) [-30|97.5] "degC"  BCM
 SG_ Batt_Temp_3 : 16|8@1+ (0.5,-30) [-30|97.5] "degC"  BCM
 SG_ Batt_Temp_2 : 8|8@1+ (0.5,-30) [-30|97.5] "degC"  BCM
 SG_ Batt_Temp_1 : 0|8@1+ (0.5,-30) [-30|97.5] "degC"  BCM

BO_ 1638 BMS_SW_HW_Versions: 8 BMS
 SG_ BMS_HW_Minor_Ver : 56|8@1+ (1,0) [0|255] ""  BCM
 SG_ BMS_HW_Major_Ver : 48|8@1+ (1,0) [0|255] ""  BCM
 SG_ BMS_FW_Minor_Ver : 8|8@1+ (1,0) [0|255] ""  BCM
 SG_ BMS_FW_Major_Ver : 0|8@1+ (1,0) [0|255] ""  BCM
 SG_ BMS_FW_BugFix_Ver : 16|8@1+ (1,0) [0|255] ""  BCM
 SG_ BMS_BL_Minor_Ver : 32|8@1+ (1,0) [0|255] ""  BCM
 SG_ BMS_BL_Major_Ver : 24|8@1+ (1,0) [0|255] ""  BCM
 SG_ BMS_BL_BugFix_Ver : 40|8@1+ (1,0) [0|255] ""  BCM

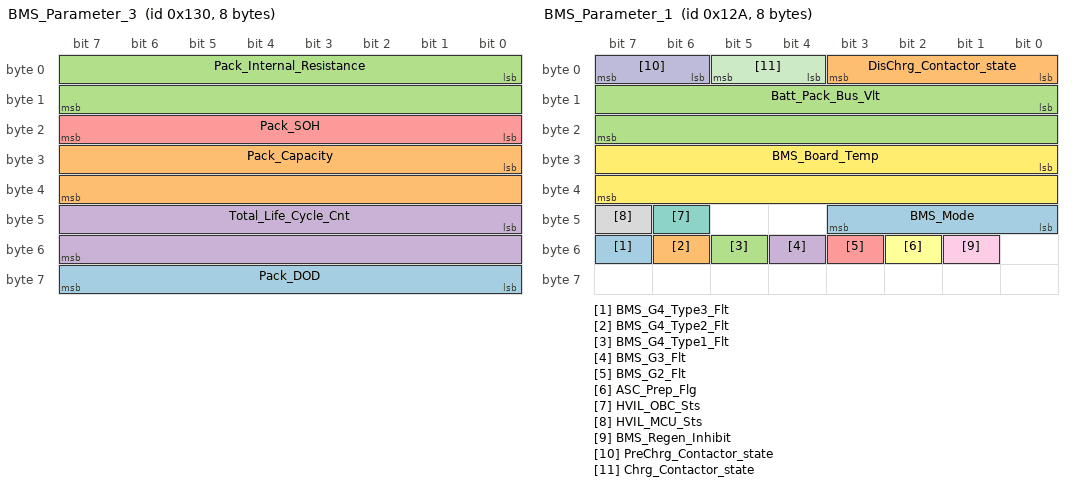
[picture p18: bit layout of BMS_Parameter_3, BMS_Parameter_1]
BO_ 304 BMS_Parameter_3: 8 BMS
 SG_ Pack_DOD : 56|8@1+ (0.5,0) [0|127.5] ""  BCM
 SG_ Pack_Capacity : 24|16@1+ (0.01,0) [0|100] ""  BCM
 SG_ Pack_Internal_Resistance : 0|16@1+ (1,0) [0|65535] ""  BCM
 SG_ Total_Life_Cycle_Cnt : 40|16@1+ (1,0) [0|65535] ""  BCM
 SG_ Pack_SOH : 16|8@1+ (0.5,0) [0|100] ""  HU,BCM

BO_ 302 BMS_Parameter_2_Limit: 8 BMS
 SG_ Delta_Vlt : 16|16@1+ (1,0) [0|65535] "mv"  BCM
 SG_ Delta_Temp : 8|8@1+ (0.5,-50) [-50|77.5] "degC"  BCM
 SG_ Effective_Batt_Temp : 0|8@1+ (0.5,-50) [-50|77.5] "degC"  BCM
 SG_ Load_Vlt : 32|16@1+ (0.01,0) [0|655.35] "V"  BCM
 SG_ Pack_Avail_Energy : 48|16@1+ (0.01,0) [0|655.35] "Volt"  BCM

BO_ 298 BMS_Parameter_1: 8 BMS
 SG_ BMS_G4_Type3_Flt : 55|1@1+ (1,0) [0|1] ""  BCM
 SG_ BMS_G4_Type2_Flt : 54|1@1+ (1,0) [0|1] ""  BCM
 SG_ BMS_G4_Type1_Flt : 53|1@1+ (1,0) [0|1] ""  BCM
 SG_ BMS_G3_Flt : 52|1@1+ (1,0) [0|1] ""  BCM
 SG_ BMS_G2_Flt : 51|1@1+ (1,0) [0|1] ""  BCM
 SG_ ASC_Prep_Flg : 50|1@1+ (1,0) [0|1] ""  BCM,BMS,MCU
 SG_ HVIL_OBC_Sts : 46|1@1+ (1,0) [0|1] ""  BCM
 SG_ HVIL_MCU_Sts : 47|1@1+ (1,0) [0|1] ""  BCM
 SG_ BMS_Regen_Inhibit : 49|1@1+ (1,0) [0|1] ""  BCM
 SG_ PreChrg_Contactor_state : 6|2@1+ (1,0) [0|3] ""  BCM
 SG_ Chrg_Contactor_state : 4|2@1+ (1,0) [0|3] ""  OBC,MCU,BCM
 SG_ BMS_Board_Temp : 24|16@1+ (0.01,-50) [-50|605.35] "degC"  BCM
 SG_ BMS_Mode : 40|4@1+ (1,0) [0|15] ""  OBC,BCM
 SG_ DisChrg_Contactor_state : 0|4@1+ (1,0) [0|15] ""  OBC,MCU,BCM
 SG_ Batt_Pack_Bus_Vlt : 8|16@1+ (0.01,0) [0|655.35] "V"  OBC,BCM

BO_ 1287 BMS_CELL_VLT_7: 8 BMS
 SG_ Cell_Vlt_Cell_28 : 48|16@1+ (0.001,0) [0|65.535] "Volt"  BCM
 SG_ Cell_Vlt_Cell_27 : 32|16@1+ (0.001,0) [0|65.535] "Volt"  BCM
 SG_ Cell_Vlt_Cell_26 : 16|16@1+ (0.001,0) [0|65.535] "Volt"  BCM
 SG_ Cell_Vlt_Cell_25 : 0|16@1+ (0.001,0) [0|65.535] "Volt"  BCM

BO_ 1286 BMS_CELL_VLT_6: 8 BMS
 SG_ Cell_Vlt_Cell_24 : 48|16@1+ (0.001,0) [0|65.535] "Volt"  BCM
 SG_ Cell_Vlt_Cell_23 : 32|16@1+ (0.001,0) [0|65.535] "Volt"  BCM
 SG_ Cell_Vlt_Cell_22 : 16|16@1+ (0.001,0) [0|65.535] "Volt"  BCM
 SG_ Cell_Vlt_Cell_21 : 0|16@1+ (0.001,0) [0|65.535] "Volt"  BCM

BO_ 1285 BMS_CELL_VLT_5: 8 BMS
 SG_ Cell_Vlt_Cell_20 : 48|16@1+ (0.001,0) [0|65.535] "Volt"  BCM
 SG_ Cell_Vlt_Cell_19 : 32|16@1+ (0.001,0) [0|65.535] "Volt"  BCM
 SG_ Cell_Vlt_Cell_18 : 16|16@1+ (0.001,0) [0|65.535] "Volt"  BCM
 SG_ Cell_Vlt_Cell_17 : 0|16@1+ (0.001,0) [0|65.535] "Volt"  BCM

BO_ 1283 BMS_CELL_VLT_4: 8 BMS
 SG_ Cell_Vlt_Cell_16 : 48|16@1+ (0.001,0) [0|65.535] "Volt"  BCM
 SG_ Cell_Vlt_Cell_15 : 32|16@1+ (0.001,0) [0|65.535] "Volt"  BCM
 SG_ Cell_Vlt_Cell_14 : 16|16@1+ (0.001,0) [0|65.535] "Volt"  BCM
 SG_ Cell_Vlt_Cell_13 : 0|16@1+ (0.001,0) [0|65.535] "Volt"  BCM

BO_ 1282 BMS_CELL_VLT_3: 8 BMS
 SG_ Cell_Vlt_Cell_9 : 0|16@1+ (0.001,0) [0|65.535] "Volt"  BCM
 SG_ Cell_Vlt_Cell_12 : 48|16@1+ (0.001,0) [0|65.535] "Volt"  BCM
 SG_ Cell_Vlt_Cell_11 : 32|16@1+ (0.001,0) [0|65.535] "Volt"  BCM
 SG_ Cell_Vlt_Cell_10 : 16|16@1+ (0.001,0) [0|65.535] "Volt"  BCM

BO_ 1281 BMS_CELL_VLT_2: 8 BMS
 SG_ Cell_Vlt_Cell_8 : 48|16@1+ (0.001,0) [0|65.535] "Volt"  BCM
 SG_ Cell_Vlt_Cell_7 : 32|16@1+ (0.001,0) [0|65.535] "Volt"  BCM
 SG_ Cell_Vlt_Cell_6 : 16|16@1+ (0.001,0) [0|65.535] "Volt"  BCM
 SG_ Cell_Vlt_Cell_5 : 0|16@1+ (0.001,0) [0|65.535] "Volt"  BCM

BO_ 1280 BMS_CELL_VLT_1: 8 BMS
 SG_ Cell_Vlt_Cell_4 : 48|16@1+ (0.001,0) [0|65.535] "Volt"  BCM
 SG_ Cell_Vlt_Cell_3 : 32|16@1+ (0.001,0) [0|65.535] "Volt"  BCM
 SG_ Cell_Vlt_Cell_2 : 16|16@1+ (0.001,0) [0|65.535] "Volt"  BCM
 SG_ Cell_Vlt_Cell_1 : 0|16@1+ (0.001,0) [0|65.535] "Volt"  BCM

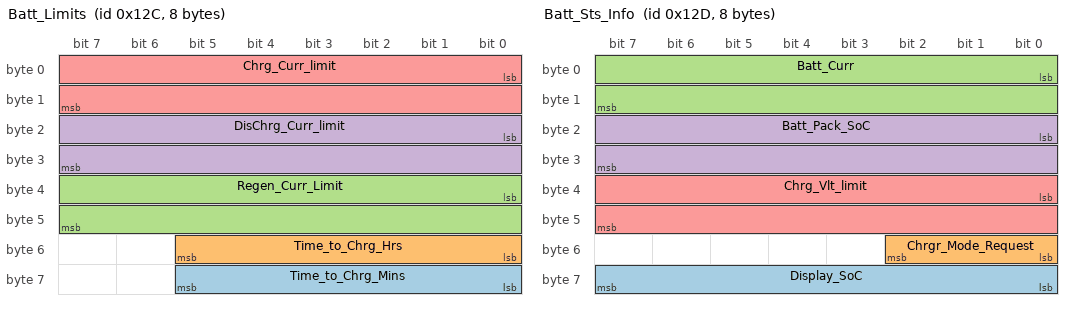
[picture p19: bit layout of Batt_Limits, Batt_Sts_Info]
BO_ 300 Batt_Limits: 8 BMS
 SG_ Time_to_Chrg_Mins : 56|6@1+ (1,0) [0|63] "Mins"  HU,BCM
 SG_ Time_to_Chrg_Hrs : 48|6@1+ (1,0) [0|63] "Hrs"  HU,BCM
 SG_ Regen_Curr_Limit : 32|16@1+ (0.01,0) [0|655.35] "Amp"  BCM,MCU,HU
 SG_ DisChrg_Curr_limit : 16|16@1+ (0.01,-400) [-400|255.35] "Amp"  MCU,BCM
 SG_ Chrg_Curr_limit : 0|16@1+ (0.01,0) [0|655.35] "Amp"  MCU,OBC,BCM

BO_ 301 Batt_Sts_Info: 8 BMS
 SG_ Display_SoC : 56|8@1+ (1,0) [0|100] "%"  MCU,BCM,HU
 SG_ Chrgr_Mode_Request : 48|3@1+ (1,0) [0|7] ""  OBC,BCM
 SG_ Batt_Curr : 0|16@1+ (0.01,-300) [-300|355.35] "Amp"  HU,BCM
 SG_ Batt_Pack_SoC : 16|16@1+ (0.01,0) [0|655.35] "%"  MCU,BCM
 SG_ Chrg_Vlt_limit : 32|16@1+ (0.01,0) [0|655.35] "V"  OBC,BCM

CM_ SG_ 564 UnIntd_Excess_Regen_Flt "G2";
CM_ SG_ 564 UnIntd_Regen_Flt "G2";
CM_ SG_ 866 Range_Gain "KM gained with every 1% increment of SOC during Charge";
CM_ SG_ 342 E_SIM_Sts "ESim status check bit";
CM_ SG_ 342 LTE_Latency "LTE Latency required 
range 60 to 98";
CM_ SG_ 342 LTE_Link_Mode "LTE mode differentiation
bit,
LTE FDD-B1/ 2/ 3/ 4/ 5/ 7/ 8/ 20/ 28

LTE TDD -B38/ 40/ 41";
CM_ SG_ 342 LTE_Conn_Sts "LTE signal check bit 
according to the requirement";
CM_ SG_ 341 GNSS_Conn_Sts "GNSS signal check bit 
according to the requirement";
CM_ SG_ 341 Bluetooth_Conn_Sts "Bluetooth signal check bit 
according to the requirement";
CM_ SG_ 341 Wifi_Conn_sts "WiFi signal check bit according to the requirement";
CM_ SG_ 341 Wifi_RSSI_Mode "Bandwidth differentiation
bit (2.4GHz & 5GHz)";
CM_ SG_ 561 Regen_Min_Speed "Minimum Threshold of RPM for Regen";
CM_ SG_ 371 Regen_Brake_Control "Regen_Brake_Control in Percentage from SOM";
CM_ SG_ 371 Regen_Coast_Control "Regen_Coast_Controll in Percentage from SOM";
CM_ SG_ 371 Throttle_Map_Control "Throttle_Map Control in Percentage from SOM";
CM_ SG_ 371 Power_Output_Control "Power Performacne Control in Percentage from SOM";
CM_ SG_ 371 Traction_Control "Traction_Control Setting from SOM";
CM_ SG_ 339 SOM_Range_Acquired "KM gained with every 1% increment of SOC during Charge";
CM_ SG_ 339 SOM_Range_Gain "KM gained with every 1% increment of SOC during Charge";
CM_ SG_ 865 Range_Acquired "Total Accumulated Range w.r.t Charge Amount Selected by the user ";
CM_ SG_ 1288 BAL_Sts "Balancing Status
";
CM_ SG_ 302 Delta_Temp "Difference b/w cell max temp and cell min temp
";
CM_ SG_ 302 Load_Vlt "Battery Charging Peak current";
CM_ SG_ 302 Pack_Avail_Energy "Sum of 28 cell voltages";
CM_ SG_ 298 HVIL_MCU_Sts "Difference b/w max temp and min temp
";
CM_ SG_ 298 BMS_Board_Temp "Temperature of BMS board";
BA_DEF_ SG_  "GenSigStartValue" HEX 0 15;
BA_DEF_ BO_  "GenMsgCycleTime" INT 0 5000;
BA_DEF_ BO_  "GenMsgSendType" ENUM  "Cyclic","Event","Unused";
BA_DEF_  "BusType" STRING ;
BA_DEF_DEF_  "GenSigStartValue" 0;
BA_DEF_DEF_  "GenMsgCycleTime" 100;
BA_DEF_DEF_  "GenMsgSendType" "Cyclic";
BA_DEF_DEF_  "BusType" "CAN";
BA_ "GenMsgCycleTime" BO_ 772 5;
BA_ "GenMsgCycleTime" BO_ 315 10;
BA_ "GenMsgCycleTime" BO_ 866 5000;
BA_ "GenMsgCycleTime" BO_ 2023 0;
BA_ "GenMsgSendType" BO_ 2023 1;
BA_ "GenMsgCycleTime" BO_ 395 0;
BA_ "GenMsgSendType" BO_ 395 1;
BA_ "GenMsgCycleTime" BO_ 393 2000;
BA_ "GenMsgCycleTime" BO_ 546 2000;
BA_ "GenMsgCycleTime" BO_ 392 2000;
BA_ "GenMsgCycleTime" BO_ 129 50;
BA_ "GenMsgCycleTime" BO_ 128 50;
BA_ "GenMsgCycleTime" BO_ 374 10;
BA_ "GenMsgCycleTime" BO_ 375 10;
BA_ "GenMsgCycleTime" BO_ 391 2000;
BA_ "GenMsgCycleTime" BO_ 390 2000;
BA_ "GenMsgCycleTime" BO_ 373 2000;
BA_ "GenMsgCycleTime" BO_ 1229 5000;
BA_ "GenMsgCycleTime" BO_ 1536 5000;
BA_ "GenMsgCycleTime" BO_ 1618 0;
BA_ "GenMsgSendType" BO_ 1618 1;
BA_ "GenMsgCycleTime" BO_ 576 500;
BA_ "GenMsgCycleTime" BO_ 343 1000;
BA_ "GenMsgCycleTime" BO_ 80 10;
BA_ "GenMsgCycleTime" BO_ 2031 0;
BA_ "GenMsgSendType" BO_ 2031 1;
BA_ "GenMsgCycleTime" BO_ 2027 0;
BA_ "GenMsgSendType" BO_ 2027 1;
BA_ "GenMsgCycleTime" BO_ 2030 0;
BA_ "GenMsgSendType" BO_ 2030 1;
BA_ "GenMsgCycleTime" BO_ 2029 0;
BA_ "GenMsgSendType" BO_ 2029 1;
BA_ "GenMsgCycleTime" BO_ 1604 5000;
BA_ "GenMsgCycleTime" BO_ 2026 0;
BA_ "GenMsgSendType" BO_ 2026 1;
BA_ "GenMsgCycleTime" BO_ 881 200;
BA_ "GenMsgCycleTime" BO_ 2028 0;
BA_ "GenMsgSendType" BO_ 2028 1;
BA_ "GenMsgCycleTime" BO_ 1616 200;
BA_ "GenMsgCycleTime" BO_ 2019 0;
BA_ "GenMsgSendType" BO_ 2019 1;
BA_ "GenMsgCycleTime" BO_ 82 10;
BA_ "GenMsgCycleTime" BO_ 2022 0;
BA_ "GenMsgSendType" BO_ 2022 1;
BA_ "GenMsgCycleTime" BO_ 2021 0;
BA_ "GenMsgSendType" BO_ 2021 1;
BA_ "GenMsgCycleTime" BO_ 2018 0;
BA_ "GenMsgSendType" BO_ 2018 1;
BA_ "GenMsgCycleTime" BO_ 2020 0;
BA_ "GenMsgSendType" BO_ 2020 1;
BA_ "GenMsgCycleTime" BO_ 81 10;
BA_ "GenMsgCycleTime" BO_ 1585 5000;
BA_ "GenMsgCycleTime" BO_ 1288 200;
BA_ "GenMsgCycleTime" BO_ 1638 5000;
BA_ "GenMsgCycleTime" BO_ 304 500;
BA_ "GenSigStartValue" SG_ 299 MTC_Lamp_Warning 6;
BA_ "GenSigStartValue" SG_ 299 ABS_Warn_Lamp 1;
VAL_ 1800 Reset_reason 5 "Controller_Wakeup" 4 "WTDG" 3 "SoftReset" 2 "HardReset" 1 "PowerOFF" 0 "SNA" ;
VAL_ 1800 Wakeup_reason 6 "IMU" 5 "Charger" 4 "RTC" 3 "LTE" 2 "BLE" 1 "SSB" 0 "SNA" ;
VAL_ 564 MCU_SBC_G4_Flt 1 "ERROR" 0 "No Error" ;
VAL_ 564 MCU_SBC_G2_Flt 1 "ERROR" 0 "No Error" ;
VAL_ 564 MCU_GateDriver_G4_Flt 1 "ERROR" 0 "No Error" ;
VAL_ 564 MCU_Flt_On_Axis_G4_Failure 1 "ERROR" 0 "No Error" ;
VAL_ 564 MCU_Flt_On_Axis_G2_Failure 1 "ERROR" 0 "No Error" ;
VAL_ 564 NVM_CRC_Flt 1 "ERROR" 0 "No Error" ;
VAL_ 564 UnIntd_Excess_Regen_Flt 1 "ERROR" 0 "No Error" ;
VAL_ 564 UnIntd_Regen_Flt 1 "ERROR" 0 "No Error" ;
VAL_ 315 MSC_Trq_Ctrl_mode 3 "Reserved" 2 "MTC Control Required" 1 "MDTC Control Required" 0 "No Control Required" ;
VAL_ 571 Active_ShrtCkt_Sts 3 "Invalid" 2 "Completed" 1 "InProgress" 0 "Not Active" ;
VAL_ 395 SW8_CS 9 "HSD_IC8_SW_Err" 8 "Wireless_CHG_Sly_OL_Err" 7 "Wireless_CHG_OC_Err" 6 "Wireless_CHG_Sly__STB_Flt" 5 "Wireless_CHG_Sly_STG_Flt" 4 "PD_USB_CHG_Sly_OL_Err" 3 "PD_USB_CHG_OC_Err" 2 "PD_USB_CHG_Sly__STB_Flt" 1 "PD_USB_CHG_Sly_STG_Flt" 0 "No Error" ;
VAL_ 395 SW7_CS 9 "HSD_IC7_SW_Err" 8 "PD_Accs_Sly_OL_Err" 7 "PD_Accs_Sly_OC_Err" 6 "PD_Accs_Sly__STB_Flt" 5 "PD_Accs_Sly_STG_Flt" 4 "EHBL_Sly_OL_Err" 3 "EHBL_Sly_OC_Err" 2 "EHBL_Sly__STB_Flt" 1 "EHBL_Sly_STG_Flt" 0 "No Error" ;
VAL_ 395 SW6_CS 9 "HSD_IC6_SW_Err" 8 "OBD2_Sly_OL_Err" 7 "OBD2_Sly_OC_Err" 6 "OBD2_Sly__STB_Flt" 5 "OBD2_Sly_STG_Flt" 4 "HB_Sly_OL_Err" 3 "HB_Sly_OC_Err" 2 "HB_Sply__STB_Flt" 1 "HB_Sly_STG_Flt" 0 "No Error" ;
VAL_ 395 SW5_CS 9 "HSD_IC5_SW_Err" 8 "LB_Sly_OL_Err" 7 "LB_Sly_OC_Err" 6 "LB_Sly__STB_Flt" 5 "LB_Sly_STG_Flt" 4 "Horn_Sly_OL_Err" 3 "Horn_Sly_OC_Err" 2 "Horn_Sly__STB_Flt" 1 "Horn_Sly__STG_Flt" 0 "No Error" ;
VAL_ 395 SW4_CS 17 "HSD_IC4_SW_Err" 16 "RES_2_SLY_OL_Err" 15 "RES_2_SLY_OC_Err" 14 "RES_2_SLY_STB_Flt" 13 "RES_2_SLY_STG_Flt" 12 "LSC_SLY_OL_Err" 11 "LSC_SLY_OC_Err" 10 "LSC_SLY__STB_Flt" 9 "LSC_SLY_STG_Flt" 8 "Tail_Lamp_Sly_OL_Err" 7 "Tail_Lamp_Sly_OC_Err" 6 "Tail_Lamp_Sly__STB_Flt" 5 "Tail_Lamp_Sly_STG_Flt" 4 "CLUSTER_Sly_OL_Err" 3 "CLUSTER_Sly_OC_Err" 2 "CLUSTER_Sly__STB_Flt" 1 "CLUSTER_Sly_STG_Flt" 0 "No Error" ;
VAL_ 395 SW3_CS 13 "HSD_IC3_SW_Err" 12 "IMU_ABS_SLY_OL_Err" 11 "IMU_ABS_SLY_OC_Err" 10 "IMU_ABS_SLY_STB_Flt" 9 "IMU_ABS_SLY_STG_Flt" 8 "NUM_Plate_Sly_OL_Err" 7 "NUM_Plate_Sly_OC_Err" 6 "NUM_Plate_Sly__STB_Flt" 5 "NUM_Plate_Sly_STG_Flt" 4 "Stop_Lamp_Sly_OL_Err" 3 "Stop_Lamp_Sly_OC_Err" 2 "Stop_Lamp_Sly__STB_Flt" 1 "Stop_Lamp_Sly_STG_Flt" 0 "No Error" ;
VAL_ 395 SW2_CS 17 "HSD_IC2_SW_Err" 16 "RES_3_SLY_OL_Err" 15 "RES_3_SLY_OC_Err" 14 "RES_3_SLY_STB_Flt" 13 "RES_3_SLY_STG_Flt" 12 "SSB_RING_SLY_OL_Err" 11 "SSB_RING_SLY_OC_Err" 10 "SSB_RING_SLY_STB_Flt" 9 "SSB_RING_SLY_STG_Flt" 8 "MCU_SLY_OL_Err" 7 "MCU_SLY_OC_Err" 6 "MCU_SLY_STB_Flt" 5 "MCU_SLY_STG_Flt" 4 "POS_Lamp_Sly_OL_Err" 3 "POS_Lamp_Sly_OC_Err" 2 "POS_Lamp_Sly_STB_Flt" 1 "POS_Lamp_Sly_STG_Flt" 0 "No Error" ;
VAL_ 395 SW1_CS 13 "HSD_IC1_SW_Err" 12 "RES_1_SLY_OL_Err" 11 "RES_1_SLY_OC_Err" 10 "RES_1_SLY_STB_Flt" 9 "RES_1_SLY_STG_Flt" 8 "CEDL_SLY_OL_Err" 7 "CEDL_SLY_OC_Err" 6 "CEDL_SLY_STB_Flt" 5 "CEDL_SLY_STG_Flt" 4 "RSC_SLY_OL_Err" 3 "RSC_SLY_OC_Err" 2 "RSC_SLY_STB_Flt" 1 "RSC_SLY_STG_Flt" 0 "No Error" ;
VAL_ 342 E_SIM_Sts 1 "Pass" 0 "Fail" ;
VAL_ 342 LTE_Link_Mode 1 "5GHz" 0 "2.4GHz" ;
VAL_ 342 LTE_Conn_Sts 1 "Pass" 0 "Fail" ;
VAL_ 341 GNSS_Conn_Sts 1 "Pass" 0 "Fail" ;
VAL_ 341 Bluetooth_Conn_Sts 1 "Pass" 0 "Fail" ;
VAL_ 341 Wifi_Conn_sts 1 "Pass" 0 "Fail" ;
VAL_ 341 Wifi_RSSI_Mode 1 "5GHz" 0 "2.4GHz" ;
VAL_ 160 Proximity_Cmd 2 "Unlock" 1 "Lock" 0 "SNA" ;
VAL_ 160 BLE_Pairing_sts 2 "Pairing_Success" 1 "Pairing_Unsuccessfull" 0 "SNA" ;
VAL_ 160 BLE_Connectiom_sts 2 "BLE_Connected" 1 "BLE_Disconnected" 0 "SNA" ;
VAL_ 160 BLE_Cmd 2 "Unlock" 1 "Lock" 0 "SNA" ;
VAL_ 129 RH_LIN_Resp_Error 1 "ON" 0 "OFF" ;
VAL_ 129 RH_LIN_Faults 2 "LIN_Checksum_Error" 1 "LIN_Synchronization_Error

" 0 "No_Fault

" ;
VAL_ 129 Hazard_Button_Fault 4 "Open_Circuit" 3 "STB" 2 "STG" 1 "Stuck" 0 "No_Fault" ;
VAL_ 129 Cruise_Button_Fault 1 "Stuck" 0 "No_Fault" ;
VAL_ 129 Cruise 1 "ON" 0 "OFF" ;
VAL_ 129 RH_Input_Under_Voltage 1 "ERROR" 0 "No Error" ;
VAL_ 129 RH_Input_Over_Voltage 1 "ERROR" 0 "No Error" ;
VAL_ 129 Aux_Button_Fault 1 "Stuck" 0 "No_Fault" ;
VAL_ 129 Mic_Button_Fault 1 "Stuck" 0 "No_Fault" ;
VAL_ 129 KILL_Switch_Button_Fault 1 "Stuck" 0 "No_Fault" ;
VAL_ 129 Aux 1 "ON" 0 "OFF" ;
VAL_ 129 Mic 1 "ON" 0 "OFF" ;
VAL_ 129 Kill_Switch 1 "ON" 0 "OFF" ;
VAL_ 129 Hazard 1 "On" 0 "Off" ;
VAL_ 128 LH_LIN_Resp_Error 1 "ON" 0 "OFF" ;
VAL_ 128 LH_LIN_Faults 2 "LIN_Checksum_Error" 1 "LIN_Synchronization_Error

" 0 "No_Fault

" ;
VAL_ 128 Mode_Down_Button_Fault 4 "Open_Circuit" 3 "STB" 2 "STG" 1 "Stuck" 0 "No_Fault" ;
VAL_ 128 Mode_Up_Button_Fault 4 "Open_Circuit" 3 "STB" 2 "STG" 1 "Stuck" 0 "No_Fault" ;
VAL_ 128 Pass_Beam_Button_Fault 4 "Open_Circuit" 3 "STB" 2 "STG" 1 "Stuck" 0 "No_Fault" ;
VAL_ 128 High_Beam_Button_Fault 4 "Open_Circuit" 3 "STB" 2 "STG" 1 "Stuck" 0 "No_Fault" ;
VAL_ 128 Home_Button_Fault 4 "Open_Circuit" 3 "STB" 2 "STG" 1 "Stuck" 0 "No_Fault" ;
VAL_ 128 LH_Input_Under_Voltage 1 "ERROR" 0 "No Error" ;
VAL_ 128 LH_Input_Over_Voltage 1 "ERROR" 0 "No Error" ;
VAL_ 128 RH_Ind_Button_Fault 1 "Stuck" 0 "No_Fault" ;
VAL_ 128 LH_Ind_Button_Fault 1 "Stuck" 0 "No_Fault" ;
VAL_ 128 Ok_Button_Fault 1 "Stuck" 0 "No_Fault" ;
VAL_ 128 Right_JoyStick_Button_Fault 1 "Stuck" 0 "No_Fault" ;
VAL_ 128 Up_JoyStick_Button_Fault 1 "Stuck" 0 "No_Fault" ;
VAL_ 128 Left_JoyStick_Button_Fault 1 "Stuck" 0 "No_Fault" ;
VAL_ 128 Horn_Button_Fault 1 "Stuck" 0 "No_Fault" ;
VAL_ 128 Down_JoyStick_Button_Fault 1 "Stuck" 0 "No_Fault" ;
VAL_ 128 RH_Ind 1 "ON" 0 "OFF" ;
VAL_ 128 LH_Ind 1 "ON" 0 "OFF" ;
VAL_ 128 OK_Btn 1 "ON" 0 "OFF" ;
VAL_ 128 Mode_Dwn_Selector 1 "ON" 0 "OFF" ;
VAL_ 128 Mode_Up_Selector 1 "ON" 0 "OFF" ;
VAL_ 128 Down_Joy_Stick 1 "On" 0 "Off" ;
VAL_ 128 Up_Joy_Stick 1 "On" 0 "Off" ;
VAL_ 128 Right_Joy_Stick 1 "On" 0 "Off" ;
VAL_ 128 Left_Joy_Stick 1 "On" 0 "Off" ;
VAL_ 128 Pass_beam 1 "ON" 0 "OFF" ;
VAL_ 128 High_beam 1 "ON" 0 "OFF" ;
VAL_ 128 Home 1 "On" 0 "Off" ;
VAL_ 128 Horn 1 "ON" 0 "OFF" ;
VAL_ 565 Regen_sts 4 "COAST_FORCED_BRAKE_REGEN

" 3 "COAST_BRAKE_REGEN" 2 "COAST_FORCED_REGEN" 1 "COAST_REGEN" 0 "NOT_ACTIVE" ;
VAL_ 1230 EHBL_Pwr_Supply_cutoff_flg 1 "True" 0 "False" ;
VAL_ 1230 EHBL_Sts 5 "Invalid" 4 "Pending" 3 "Unlock_fail" 2 "Lock_fail" 1 "Unlock_Success" 0 "Lock_Success" ;
VAL_ 1230 EHBL_RotHandleBar 1 "Isuue_Warning" 0 "OFF

" ;
VAL_ 1230 EHBL_BoltSts 7 "Reserved" 6 "Reserved

" 5 "Reserved

" 4 "Reserved

" 3 "Invalid

" 2 "Pending

" 1 "Unlock

" 0 "Lock

" ;
VAL_ 1230 EHBL_Warningsafety 7 "Reserved" 6 "Reserved

" 5 "Reserved

" 4 "Reserved

" 3 "Reserved

" 2 "Reserved

" 1 "Error_1

" 0 "No_Error

" ;
VAL_ 1618 EHBL_Auth_Result 1 "Failed" 0 "Successful

" ;
VAL_ 1104 MTC_Requested_Mode 4 "MIN_OFFROAD" 3 "High" 2 "Standard" 1 "Minimum" 0 "OFF" ;
VAL_ 1104 ABS_Requested_Mode 7 "Mode_7" 6 "Mode_6

" 5 "Mode_5

" 4 "Mode_4

" 3 "Mode_3

" 2 "Mode_2

" 1 "Mode_1

" 0 "Mode_0

" ;
VAL_ 1104 Variant_Info 3 "Reserved2" 2 "L1K

" 1 "L1A

" 0 "Reserved1

" ;
VAL_ 576 IMU_Model_Monitoring 1 "True" 0 "False" ;
VAL_ 576 IMU_Wrong_Mount_Fail 1 "True" 0 "False" ;
VAL_ 576 CAN_Buss_Off_Fail 1 "True" 0 "False" ;
VAL_ 576 CAN_IMU_Signal_Fail 1 "True" 0 "False" ;
VAL_ 576 CAN_IMU_Frame_Fail 1 "True" 0 "False" ;
VAL_ 576 CAN_Frame 1 "True" 0 "False" ;
VAL_ 576 CAN_Controller_Generic_Fail 1 "True" 0 "False" ;
VAL_ 576 WSS_Generic_Fail 1 "True" 0 "False" ;
VAL_ 576 WSS_Suspicious_Fail_R 1 "True" 0 "False" ;
VAL_ 576 WSS_Suspicious_Fail_F 1 "True" 0 "False" ;
VAL_ 576 WSS_Plausibility_Fail_R 1 "True" 0 "False" ;
VAL_ 576 WSS_Plausibility_Fail_F 1 "True" 0 "False" ;
VAL_ 576 WSS_HW_Fail_R 1 "True" 0 "False" ;
VAL_ 576 WSS_HW_Fail_F 1 "True" 0 "False" ;
VAL_ 576 Pump_Motor_Reversible_Fail 1 "True" 0 "False" ;
VAL_ 576 Pump_Motor_Fail 1 "True" 0 "False" ;
VAL_ 576 UZ_Supply_UV_Flt 1 "True" 0 "False" ;
VAL_ 576 UZ_Supply_OV_Flt 1 "True" 0 "False" ;
VAL_ 576 Outlet_Valve_Fail_R 1 "True" 0 "False" ;
VAL_ 576 Outlet_Valve_Fail_F 1 "True" 0 "False" ;
VAL_ 576 Inlet_Valve_Fail_R 1 "True" 0 "False" ;
VAL_ 576 Inlet_Valve_Fail_F 1 "True" 0 "False" ;
VAL_ 576 Valve_Relay_Flt 1 "True" 0 "False" ;
VAL_ 576 Control_Unit_Fail 1 "True" 0 "False" ;
VAL_ 563 MCU_Machine_Mode 19 "Custom_Mode" 18 "Permanent_DriveOFF" 17 "Offroad_Mode" 16 "Reverse_Mode" 15 "Derate_Mode" 14 "Hill_Hold_Mode" 13 "Rain_Mode" 12 "Regen_Mode" 11 "Fault_Mode" 10 "Limp_Mode" 9 "CruiseContol_Mode" 8 "Charge_Mode" 7 "Crawl_Mode" 6 "Sport_Mode" 5 "Tour_mode" 4 "Eco_Mode" 3 "Shutdown_Mode" 2 "Idle_Mode" 1 "Init_Mode" 0 "Pre_Init_Mode" ;
VAL_ 563 MCU_12V_CutOFF_Flg 1 "True" 0 "False" ;
VAL_ 563 MCU_PreChrg_Sts 1 "Completed" 0 "NotCompleted" ;
VAL_ 340 Theft_Detection 3 "Error" 2 "Theft_detected" 1 "No_theft_detected" 0 "SNA" ;
VAL_ 340 SOM_CRateSel_PreConf 3 "Tickle" 2 "Standard" 1 "Rapid" 0 "No_Sel" ;
VAL_ 340 SOM_Boot_Ack 1 "True" 0 "False" ;
VAL_ 340 SOM_ChrgAmtSel_PreConf 7 "100%" 6 "90%" 5 "80%" 4 "70%" 3 "60%" 2 "50%" 1 "40%" 0 "No_Sel" ;
VAL_ 340 SOM_Chrg_Amt_Sel 7 "100%" 6 "90%" 5 "80%" 4 "70%" 3 "60%" 2 "50%" 1 "40%" 0 "No_Sel" ;
VAL_ 340 SOM_Chrg_Rate_Sel 3 "Tickle" 2 "Standard" 1 "Rapid" 0 "No_Sel" ;
VAL_ 340 Language_Sel_Set 7 "ITA" 6 "POR" 5 "ESP" 4 "FR" 3 "DE" 2 "US" 1 "UK" 0 "SNA" ;
VAL_ 340 Vacation_Mode 1 "ON" 0 "OFF" ;
VAL_ 340 Trip_2_Reset_flg 1 "True" 0 "False" ;
VAL_ 340 Trip_1_Reset_flg 1 "True" 0 "False" ;
VAL_ 340 Day_Night_Mode_Sel 2 "Night" 1 "Day

" 0 "Auto

" ;
VAL_ 340 Brightness_Sel 1 "Manual" 0 "Auto

" ;
VAL_ 340 ABS_Sensitivity_Sel 3 "Insensitive2" 2 "Sensitive

" 1 "Insensitive1

" 0 "Standard

" ;
VAL_ 340 ABS_State_Sel 2 "Both_OFF

" 1 "Rear_OFF

" 0 "Both_ON

" ;
VAL_ 340 Ride_Mode_Sel 6 "OFFROAD" 5 "SPORT" 4 "CUSTOM" 3 "TOUR" 2 "RAIN" 1 "ECO" 0 "SNA" ;
VAL_ 340 Hill_Hold_Setting 1 "Enable" 0 "Disable" ;
VAL_ 340 Haptic_Setting 1 "Enable" 0 "Disable" ;
VAL_ 340 Regen_Setting 1 "Enable" 0 "Disable" ;
VAL_ 80 Regen_Command 4 "Coast Forced Brake Regen" 3 "Coast Brake Regen " 2 "Coast Forced Regen" 1 "Coast Regen" 0 "Non Active" ;
VAL_ 80 Rear_Brake_Sts 1 "Applied" 0 "Not Applied" ;
VAL_ 80 Front_Brake_Sts 1 "Applied" 0 "Not Applied" ;
VAL_ 371 Regen_Brake_Control 9 "100%" 8 "90%" 7 "80%" 6 "70%" 5 "60%" 4 "50%" 3 "40%" 2 "30%" 1 "20%" 0 "10%" ;
VAL_ 371 Regen_Coast_Control 9 "100%" 8 "90%" 7 "80%" 6 "70%" 5 "60%" 4 "50%" 3 "40%" 2 "30%" 1 "20%" 0 "10%" ;
VAL_ 371 Throttle_Map_Control 9 "100%" 8 "90%" 7 "80%" 6 "70%" 5 "60%" 4 "50%" 3 "40%" 2 "30%" 1 "20%" 0 "10%" ;
VAL_ 371 Power_Output_Control 9 "100%" 8 "90%" 7 "80%" 6 "70%" 5 "60%" 4 "50%" 3 "40%" 2 "30%" 1 "20%" 0 "10%" ;
VAL_ 371 Traction_Control 3 "High" 2 "Mid" 1 "Low" 0 "OFF" ;
VAL_ 299 MTC_Lamp_Warning 6 "Signal Invalid" 5 "Cornering TC Fail" 4 "TC_User_Disabled" 3 "TC_Initialising" 2 "TC Error" 1 "TC Active Intervention" 0 "TC Active NI" ;
VAL_ 299 MTC_Mode_Selected 4 "MIN_OFFROAD" 3 "High" 2 "Standard" 1 "Minimum" 0 "OFF" ;
VAL_ 299 MTC_Mode_Permission 1 "Allowed" 0 "Denied" ;
VAL_ 299 ABS_Warn_Lamp 2 "Cornering_Err" 1 "ON" 0 "OFF" ;
VAL_ 299 ABS_Sensitivity_Sts 3 "Insensitive2_Sensitivity_offroad" 2 "Sensitive_Sensitivity_max" 1 "Insensitive_Sensitivity_min" 0 "Standard_Sensitivity" ;
VAL_ 299 Rear_Wheel_Speed_Validity 1 "Valid" 0 "Not_Valid" ;
VAL_ 299 Front_Wheel_Speed_Validity 1 "Valid" 0 "Not_Valid" ;
VAL_ 299 ABS_Mode_Permission 1 "Mode Req Allowed" 0 "Mode Req Denied" ;
VAL_ 299 ABS_Event_Active 1 "Active" 0 "Not Active" ;
VAL_ 299 ABS_Mode_Selected 7 "Mode_7" 6 "Mode_6

" 5 "Mode_5

" 4 "Mode_4

" 3 "Mode_3

" 2 "Mode_2

" 1 "Mode_1

" 0 "Mode_0

" ;
VAL_ 1290 Temp_Imbalance_Warn 1 "Fault" 0 "No Fault" ;
VAL_ 1290 BMS_LP_DCDC_Ovload_flt 1 "Fault" 0 "No Fault" ;
VAL_ 1290 BMS_Vlt_Imbalance_flt 1 "Fault" 0 "No Fault" ;
VAL_ 1290 BMS_Internal_Fault 1 "Fault" 0 "No Fault" ;
VAL_ 1290 BMS_Prechrg_Overload 1 "Fault" 0 "No Fault" ;
VAL_ 1290 BMS_OV_Permnt_Flt 1 "Fault" 0 "No Fault" ;
VAL_ 1290 BMS_UV_Permnt_Flt 1 "Fault" 0 "No Fault" ;
VAL_ 1290 Fire_Ext_Sts 1 "Connected" 0 "Not Connected" ;
VAL_ 1290 Pyro_Fuse_Sts 1 "Blown" 0 "Not_Blown" ;
VAL_ 1290 Low_SOC_Warn_15 1 "Fault" 0 "No Fault" ;
VAL_ 1290 HVIL_OBC_Err 1 "Fault" 0 "No Fault" ;
VAL_ 1290 HVIL_MCU_Err 1 "Fault" 0 "No Fault" ;
VAL_ 1290 BMS_Dischrg_Fuse_Fail 1 "Fault" 0 "No Fault" ;
VAL_ 1290 BMS_Chrgr_Fuse_Fail 1 "Fault" 0 "No Fault" ;
VAL_ 1290 LPDCDC_OP_FAIL 1 "Fault" 0 "No Fault" ;
VAL_ 1290 AFE1_Fail 1 "Fault" 0 "No Fault" ;
VAL_ 1290 Pack_Monitor_Fail 1 "Fault" 0 "No Fault" ;
VAL_ 1290 AFE_ISO_Fail_Err 1 "Fault" 0 "No Fault" ;
VAL_ 1290 AFE_SPI_Heartbeat_Fail_Err 1 "Fault" 0 "No Fault" ;
VAL_ 1290 LOW_SOC 1 "Fault" 0 "No Fault" ;
VAL_ 1290 LOW_SOC_WARN 1 "Fault" 0 "No Fault" ;
VAL_ 1290 HPDCDC_OP_FAIL 1 "Fault" 0 "No Fault" ;
VAL_ 1290 Pos_Contactor_Weld 1 "Fault" 0 "No Fault" ;
VAL_ 1290 PreChrg_Relay_Weld 1 "Fault" 0 "No Fault" ;
VAL_ 1290 OBC_CAN_Heartbeat_Err 1 "Fault" 0 "No Fault" ;
VAL_ 1290 VCU_CAN_Heartbeat_Err 1 "Fault" 0 "No Fault" ;
VAL_ 1290 BMS_DisChrg_Over_Curr 1 "Fault" 0 "No Fault" ;
VAL_ 1290 BMS_LPDCDC_CutOFF 1 "Fault" 0 "No Fault" ;
VAL_ 1290 BMS_Low_Temp_during_Drv_Err 1 "Fault" 0 "No Fault" ;
VAL_ 1290 BMS_PDU_Lock_HW 1 "Fault" 0 "No Fault" ;
VAL_ 1290 BMS_Pressure_Snsr_Err 1 "Fault" 0 "No Fault" ;
VAL_ 1290 BMS_Gas_Snsr_Err 1 "Fault" 0 "No Fault" ;
VAL_ 1290 BMS_LP_DCDC_Output_Shrt_Ckt 1 "Fault" 0 "No Fault" ;
VAL_ 1290 BMS_Cell_Temp_Imbalance 1 "Fault" 0 "No Fault" ;
VAL_ 1290 BMS_Insulation_Monitor_Err 1 "Fault" 0 "No Fault" ;
VAL_ 1290 BMS_PDU_Fail 1 "Fault" 0 "No Fault" ;
VAL_ 1290 BMS_Thermal_Runaway 1 "Fault" 0 "No Fault" ;
VAL_ 1290 BMS_PreChrg_No_Load_Detected 1 "Fault" 0 "No Fault" ;
VAL_ 1290 BMS_Short_Ckt_Detect_Err 1 "Fault" 0 "No Fault" ;
VAL_ 1290 BMS_Over_Temp_Drv_Err 1 "Fault" 0 "No Fault" ;
VAL_ 1290 BMS_Over_Temp_Drv_Warn_Info 1 "Fault" 0 "No Fault" ;
VAL_ 1290 BMS_Over_Temp_Chrg_Err 1 "Fault" 0 "No Fault" ;
VAL_ 1290 BMS_Over_Temp_Chrg_Warn_Info 1 "Fault" 0 "No Fault" ;
VAL_ 1290 BMS_Under_Vlt_Err 1 "Fault" 0 "No Fault" ;
VAL_ 1290 BMS_Under_Vlt_Warn_Info 1 "Fault" 0 "No Fault" ;
VAL_ 1290 BMS_Over_Vlt_Chrg_Err 1 "Fault" 0 "No Fault" ;
VAL_ 1290 BMS_PreChrg_Fail 1 "Fault" 0 "No Fault" ;
VAL_ 1290 BMS_Over_Curr_Chrg_Err 1 "Fault" 0 "No Fault" ;
VAL_ 1290 BMS_Curr_Snsr_Fail_Shrt_Ckt 1 "Fault" 0 "No Fault" ;
VAL_ 1290 BMS_Curr_Snsr_Fail_Open_Ckt 1 "Fault" 0 "No Fault" ;
VAL_ 1290 BMS_Low_Temp_during_Drv_Warn 1 "Fault" 0 "No Fault" ;
VAL_ 1290 BMS_Low_Temp_during_Chrg_Err 1 "Fault" 0 "No Fault" ;
VAL_ 1290 BMS_Low_Temp_Chrg_Warn_info 1 "Fault" 0 "No Fault" ;
VAL_ 1289 BMS_BattPack_Temp6_Snsr_Fail 1 "Fault" 0 "No Fault" ;
VAL_ 1289 BMS_BattPack_Temp5_Snsr_Fail 1 "Fault" 0 "No Fault" ;
VAL_ 1289 BMS_BattPack_Temp4_Snsr_Fail 1 "Fault" 0 "No Fault" ;
VAL_ 1289 BMS_BattPack_Temp3_Snsr_Fail 1 "Fault" 0 "No Fault" ;
VAL_ 1289 BMS_BattPack_Temp2_Snsr_Fail 1 "Fault" 0 "No Fault" ;
VAL_ 1289 BMS_BattPack_Temp1_Snsr_Fail 1 "Fault" 0 "No Fault" ;
VAL_ 1289 BMS_Vlt_Snsr_Fail_Cell28 1 "Fault" 0 "No Fault" ;
VAL_ 1289 BMS_Vlt_Snsr_Fail_Cell27 1 "Fault" 0 "No Fault" ;
VAL_ 1289 BMS_Vlt_Snsr_Fail_Cell26 1 "Fault" 0 "No Fault" ;
VAL_ 1289 BMS_Vlt_Snsr_Fail_Cell25 1 "Fault" 0 "No Fault" ;
VAL_ 1289 BMS_Vlt_Snsr_Fail_Cell24 1 "Fault" 0 "No Fault" ;
VAL_ 1289 BMS_Vlt_Snsr_Fail_Cell23 1 "Fault" 0 "No Fault" ;
VAL_ 1289 BMS_Vlt_Snsr_Fail_Cell22 1 "Fault" 0 "No Fault" ;
VAL_ 1289 BMS_Vlt_Snsr_Fail_Cell21 1 "Fault" 0 "No Fault" ;
VAL_ 1289 BMS_Vlt_Snsr_Fail_Cell20 1 "Fault" 0 "No Fault" ;
VAL_ 1289 BMS_Vlt_Snsr_Fail_Cell19 1 "Fault" 0 "No Fault" ;
VAL_ 1289 BMS_Vlt_Snsr_Fail_Cell18 1 "Fault" 0 "No Fault" ;
VAL_ 1289 BMS_Vlt_Snsr_Fail_Cell17 1 "Fault" 0 "No Fault" ;
VAL_ 1289 BMS_Vlt_Snsr_Fail_Cell16 1 "Fault" 0 "No Fault" ;
VAL_ 1289 BMS_Vlt_Snsr_Fail_Cell15 1 "Fault" 0 "No Fault" ;
VAL_ 1289 BMS_Vlt_Snsr_Fail_Cell14 1 "Fault" 0 "No Fault" ;
VAL_ 1289 BMS_Vlt_Snsr_Fail_Cell13 1 "Fault" 0 "No Fault" ;
VAL_ 1289 BMS_Vlt_Snsr_Fail_Cell12 1 "Fault" 0 "No Fault" ;
VAL_ 1289 BMS_Vlt_Snsr_Fail_Cell11 1 "Fault" 0 "No Fault" ;
VAL_ 1289 BMS_Vlt_Snsr_Fail_Cell10 1 "Fault" 0 "No Fault" ;
VAL_ 1289 BMS_Vlt_Snsr_Fail_Cell9 1 "Fault" 0 "No Fault" ;
VAL_ 1289 BMS_Vlt_Snsr_Fail_Cell8 1 "Fault" 0 "No Fault" ;
VAL_ 1289 BMS_Vlt_Snsr_Fail_Cell7 1 "Fault" 0 "No Fault" ;
VAL_ 1289 BMS_Vlt_Snsr_Fail_Cell6 1 "Fault" 0 "No Fault" ;
VAL_ 1289 BMS_Vlt_Snsr_Fail_Cell5 1 "Fault" 0 "No Fault" ;
VAL_ 1289 BMS_Vlt_Snsr_Fail_Cell4 1 "Fault" 0 "No Fault" ;
VAL_ 1289 BMS_Vlt_Snsr_Fail_Cell3 1 "Fault" 0 "No Fault" ;
VAL_ 1289 BMS_Vlt_Snsr_Fail_Cell2 1 "Fault" 0 "No Fault" ;
VAL_ 1289 BMS_Vlt_Snsr_Fail_Cell1 1 "Fault" 0 "No Fault" ;
VAL_ 881 HU_CRateSel_PreConf 3 "Tickle" 2 "Standard" 1 "Rapid" 0 "No_Sel" ;
VAL_ 881 HU_ChrgAmtSel_PreConf 7 "100%" 6 "90%" 5 "80%" 4 "70%" 3 "60%" 2 "50%" 1 "40%" 0 "No_Sel" ;
VAL_ 881 HU_Chrgr_Door_Cmd 1 "UNLOCK" 0 "SNA" ;
VAL_ 881 HU_Chrg_Rate_Sel 3 "Tickle" 2 "Standard" 1 "Rapid" 0 "No_Sel" ;
VAL_ 881 HU_Chrg_Amt_Sel 7 "100%" 6 "90%" 5 "80%" 4 "70%" 3 "60%" 2 "50%" 1 "40%" 0 "No_Sel" ;
VAL_ 881 HU_Pwr_Supply_cutoff_flg 1 "True" 0 "False" ;
VAL_ 881 Ambient_Light_Snsr_OP 1 "Night" 0 "Day

" ;
VAL_ 1799 GMSL_Fail 1 "Fault" 0 "No Fault" ;
VAL_ 1799 HU_Backlight_Fail 1 "Fault" 0 "No Fault" ;
VAL_ 1799 HU_Internal_Flt 1 "Fault" 0 "No Fault" ;
VAL_ 1799 ALS_Fail 1 "Fault" 0 "No Fault" ;
VAL_ 1799 HU_Temp_Sensor_Fail 1 "Fault" 0 "No Fault" ;
VAL_ 1799 HU_Buss_OFF_Err 1 "Fault" 0 "No Fault" ;
VAL_ 1616 Touch_Sts 1 "ON" 0 "OFF" ;
VAL_ 268 Chrgr_Door_Pwr_Supply 1 "ON" 0 "OFF" ;
VAL_ 268 Chrgr_Door_Sts 1 "UNLOCK" 0 "SNA" ;
VAL_ 268 Harsh_Brake_flg 1 "True" 0 "False" ;
VAL_ 268 Harsh_Acc_Flg 1 "True" 0 "False" ;
VAL_ 268 Licence_Plate_Power_Supply 1 "ON" 0 "OFF" ;
VAL_ 268 Wireless_Chrgr_Sts 6 "Phone_Overheating" 5 "Charger_Error" 4 "Foreign_Object_Detection" 3 "Charging" 2 "Charging_Completed" 1 "Standby" 0 "SNA" ;
VAL_ 268 HU_Prep_Shutdown_flg 1 "True" 0 "False" ;
VAL_ 268 ABS_Heartbeat_Fail_flg 1 "True" 0 "False" ;
VAL_ 268 SSB_Illumination_Mode 7 "
EHBL_Lock_Fail" 6 "EHBL_Lock_Success" 5 "Charging_Complete
" 4 "Charging_Mode" 3 "Drive_Mode
" 2 "Park_Mode" 1 "Power_On
" 0 "SNA" ;
VAL_ 268 USB_Chrgr_Power_Supply 1 "ON" 0 "OFF" ;
VAL_ 268 Wireless_Chrgr_Power_Supply 1 "ON" 0 "OFF" ;
VAL_ 268 OBD_Power_Supply 1 "ON" 0 "OFF" ;
VAL_ 268 Mode_Down_Btn_Sts 2 "Long Press" 1 "Short Press" 0 "SNA" ;
VAL_ 268 Mode_Up_Btn_Sts 2 "Long Press" 1 "Short Press" 0 "SNA" ;
VAL_ 268 Aux_Btn_Sts 2 "Long Press" 1 "Short Press" 0 "SNA" ;
VAL_ 268 ABS_IMU_Power_Supply 1 "ON" 0 "OFF" ;
VAL_ 268 Sleep_RTC_WakeUp_flg 1 "True" 0 "False" ;
VAL_ 268 LIN_Comm_Fail_flg 1 "True" 0 "False" ;
VAL_ 268 SPI_Comm_Fail_flg 1 "True" 0 "False" ;
VAL_ 268 OBC_Hearbeat_Fail_flg 1 "True" 0 "False" ;
VAL_ 268 MCU_Hearbeat_Fail_flg 1 "True" 0 "False" ;
VAL_ 268 BMS_Hearbeat_Fail_flg 1 "True" 0 "False" ;
VAL_ 268 Auto_Lock_Flg 1 "True" 0 "False" ;
VAL_ 268 Throttle_Response_CutOFF_Flag 1 "True" 0 "False" ;
VAL_ 268 Cruise_Availibilty_Status 1 "Available" 0 "Not Available" ;
VAL_ 268 Drv_Enable 1 "Enable" 0 "Disable" ;
VAL_ 268 Stop_Lamp_Sts 1 "ON" 0 "OFF" ;
VAL_ 268 Tail_Lamp_Sts 1 "ON" 0 "OFF" ;
VAL_ 268 Ignition_Sts 1 "True" 0 "False" ;
VAL_ 268 Veh_Authentication_Flag 1 "Authenticated" 0 "Not Authenticated" ;
VAL_ 268 Position_Lamp_Power_Supply 1 "ON" 0 "OFF" ;
VAL_ 268 Tail_Lamp_Power_Supply 1 "ON" 0 "OFF" ;
VAL_ 268 Stop_Lamp_Power_Supply 1 "ON" 0 "OFF" ;
VAL_ 268 RSC_Power_Supply 1 "ON" 0 "OFF" ;
VAL_ 268 EHBL_Commands 2 "Unlock" 1 "Lock" 0 "No Operation" ;
VAL_ 268 EHBL_Power_Supply 1 "ON" 0 "OFF" ;
VAL_ 268 SOM_Power_Supply 1 "ON" 0 "OFF" ;
VAL_ 268 Speaker_Power_Supply 1 "ON" 0 "OFF" ;
VAL_ 268 Horn_Power_Supply 1 "ON" 0 "OFF" ;
VAL_ 268 LSC_Power_Supply 1 "ON" 0 "OFF" ;
VAL_ 268 Low_Beam_Power_Supply 1 "ON" 0 "OFF" ;
VAL_ 268 High_Beam_Power_Supply 1 "ON" 0 "OFF" ;
VAL_ 268 Right_Indicator_Power_Supply 1 "ON" 0 "OFF" ;
VAL_ 268 Left_Indicator_Power_Supply 1 "ON" 0 "OFF" ;
VAL_ 268 HU_Power_Supply 1 "ON" 0 "OFF" ;
VAL_ 268 MCU_Power_Supply 1 "ON" 0 "OFF" ;
VAL_ 268 Chrgr_Plugin 2 "Slow Charger Connected" 1 "Fast Charger Connected" 0 "Charger Not Connected" ;
VAL_ 339 Chrgr_Door_Cmd 1 "UNLOCK" 0 "SNA" ;
VAL_ 339 OTA_Status_Info 3 "Faiure" 2 "Completed" 1 "In progress" 0 "SNA" ;
VAL_ 339 OTA_Req_Sts 1 "True" 0 "False" ;
VAL_ 339 LTE_Cmd 2 "Unlock" 1 "Lock" 0 "SNA" ;
VAL_ 339 SOM_Datasync_Sts 2 "Aborted" 1 "Completed" 0 "InProgress" ;
VAL_ 339 Vehicle_Interaction_Flg 1 "True" 0 "False" ;
VAL_ 339 Passcode_Trigger 1 "ON" 0 "OFF" ;
VAL_ 339 Passcode_Authentication 1 "Successful" 0 "Unsuccessful" ;
VAL_ 339 SOM_Sts 4 "Screen ON" 3 "Bootup" 2 "Power Off" 1 "Deep Sleep" 0 "Light Sleep" ;
VAL_ 339 SOM_HeartBeat_Fail 1 "Failure" 0 "No Failure" ;
VAL_ 82 Throttle_Deviation_Flt 1 "DEVIATION_ERROR" 0 "NO_ERROR" ;
VAL_ 82 Throttle_2_Flt 2 "TH2_UNDER_V_ERR" 1 "TH2_OVER_V_ERR" 0 "TH2_NOERROR" ;
VAL_ 82 Throttle_1_Flt 2 "TH1_UNDER_V_ERR" 1 "TH1_OVER_V_ERR" 0 "TH1_NOERROR" ;
VAL_ 267 Ride_Mode_Set 7 "LIMPHOME" 6 "OFFROAD" 5 "SPORT" 4 "CUSTOM" 3 "TOUR" 2 "RAIN" 1 "ECO" 0 "SNA" ;
VAL_ 267 Vehicle_Mode_Lvl_3 15 "OFFROAD" 14 "SPORT" 13 "CRAWL" 12 "REVERSE" 11 "LIMPHOME" 10 "CUSTOM" 9 "TOUR" 8 "RAIN" 7 "ECO" 6 "UNLOCK_FAIL" 5 "LOCK_FAIL" 4 "UNLOCKING" 3 "LOCKING" 2 "UNLOCK" 1 "LOCK" 0 "SNA" ;
VAL_ 267 Vehicle_Mode_Lvl_2 17 "ALARM" 16 "ON_BOARD_SLOW" 15 "ON_BOARD_FAST" 14 "RIDING" 13 "SLOW_MODE" 12 "PARK" 11 "OTA" 10 "CHARGE_FAULT" 9 "CHARGE_IDLE" 8 "DIAGNOSTIC" 7 "BOOT_UP" 6 "POWER_UP" 5 "FORCED_OTA" 4 "SHUT_OFF" 3 "VACATION" 2 "DEEP_SLEEP" 1 "SLEEP" 0 "VL2_SNA" ;
VAL_ 267 Vehicle_Mode_Lvl_1 5 "CHARGE" 4 "DRIVE" 3 "STANDBY" 2 "AWAKE" 1 "SLEEP" 0 "VL1_SNA" ;
VAL_ 266 OTA_Resp_Sts 4 "Deny_Charge" 3 "Deny_Drive" 2 "Deny_LOW_SOC" 1 "Allowed" 0 "SNA" ;
VAL_ 266 Mic_Sts 2 "Long Press" 1 "Short Press" 0 "SNA" ;
VAL_ 266 Cruise_btn_Sts 2 "Long Press" 1 "Short Press" 0 "SNA" ;
VAL_ 266 Ok_Sts 2 "Long Press" 1 "Short Press" 0 "SNA" ;
VAL_ 266 Home_Sts 2 "Long Press" 1 "Short Press" 0 "SNA" ;
VAL_ 266 Down_Joy_Stick_Sts 2 "Long Press" 1 "Short Press" 0 "SNA" ;
VAL_ 266 Up_Joy_Stick_Sts 2 "Long Press" 1 "Short Press" 0 "SNA" ;
VAL_ 266 Right_Joy_Stick_Sts 2 "Long Press" 1 "Short Press" 0 "SNA" ;
VAL_ 266 Left_Joy_Stick_Sts 2 "Long Press" 1 "Short Press" 0 "SNA" ;
VAL_ 266 Start_Stop_Button_Sts 2 "Long Press" 1 "Short Press" 0 "SNA" ;
VAL_ 266 SOS_Btn 1 "True" 0 "False" ;
VAL_ 266 Start_Stop_Btn 1 "True" 0 "False" ;
VAL_ 266 Hill_Hold_Command 3 "SystemDeactivate" 2 "UserDeactivate" 1 "Activate" 0 "Not Activate" ;
VAL_ 266 Cruise_Control_Req 5 "System Deactivate" 4 "User Deactivate" 3 "Deactivate" 2 "Activation Confirmed" 1 "Activated Set" 0 "Not Activated" ;
VAL_ 865 VCU_CRate_Sel_PreConf 3 "Tickle" 2 "Standard" 1 "Rapid" 0 "No_Sel" ;
VAL_ 865 Tow_Detection_Flg 2 "Tamper_Detected" 1 "Tow_Detected" 0 "No_Detection" ;
VAL_ 865 Crash_Detection_Flg 3 "High_Crash_Detected" 2 "Mid_Crash_Detected" 1 "Low_Crash_Detected" 0 "No_Crash" ;
VAL_ 865 Indicators_Fault 8 "LI_SC_RI_OC_Err" 7 "LI_OC_RI_SC_Err" 6 "LI_RI_SC_Err" 5 "LI_RI_OC_Err" 4 "RI_SC_Err" 3 "RI_OC_Err" 2 "LI_SC_Err" 1 "LI_OC_Err" 0 "No_Err" ;
VAL_ 865 VCU_Chrg_Rate_Sel 3 "Tickle" 2 "Standard" 1 "Rapid" 0 "No_Sel" ;
VAL_ 865 VCU_Chrg_Amt_Sel 7 "100%" 6 "90%" 5 "80%" 4 "70%" 3 "60%" 2 "50%" 1 "40%" 0 "No_Sel" ;
VAL_ 865 VCU_ChrgAmtSel_PreConf 7 "100%" 6 "90%" 5 "80%" 4 "70%" 3 "60%" 2 "50%" 1 "40%" 0 "No_Sel" ;
VAL_ 865 Regen_Availibilty_Flg 1 "Available" 0 "Not_Available

" ;
VAL_ 865 Hill_Hold_TTL 3 "Not_Available" 2 "Abt_to_Deactivate

" 1 "Active

" 0 "Not_Active

" ;
VAL_ 865 Regen_TTL 2 "Active" 1 "Not_Active

" 0 "Not_Available

" ;
VAL_ 865 Cruise_Control_TTL 4 "Fault" 3 "Active

" 2 "Not_Active

" 1 "Not_Available

" 0 "Default

" ;
VAL_ 865 Position_Lamp_TTL 1 "ON" 0 "OFF" ;
VAL_ 865 FrontLight_TTL 3 "Error" 2 "High Beam" 1 "Low Beam" 0 "No Operation" ;
VAL_ 865 Indicators_TTL 3 "Hazard_TTL" 2 "RightIndicator_TT:" 1 "LeftIndicator_TTL" 0 "No Operation" ;
VAL_ 865 Side_Stand_Sts 4 "ShortCktFlt" 3 "Open_ShortCktFlt" 2 "Applied" 1 "Removed" 0 "SNA" ;
VAL_ 423 HPDCDC_Output_Sts 1 "Enable" 0 "Disable" ;
VAL_ 423 Control_and_Proximity_Sts 1 "Enable" 0 "Disable" ;
VAL_ 423 OBC_Coolant_FAN_Sts 1 "Enable" 0 "Disable" ;
VAL_ 423 OBC_Output_Sts 1 "Enable" 0 "Disable" ;
VAL_ 1294 OBC_Output_Under_Vlt_Flt 1 "ERROR" 0 "No Error" ;
VAL_ 1294 DCDC_Output_Over_Vlt_Flt 1 "ERROR" 0 "No Error" ;
VAL_ 1294 DCDC_Temp_Snsr_Fail 1 "ERROR" 0 "No Error" ;
VAL_ 1294 DCDC_Output_Shrt_Ckt 1 "ERROR" 0 "No Error" ;
VAL_ 1294 DCDC_Output_Over_Curr 1 "ERROR" 0 "No Error" ;
VAL_ 1294 DCDC_Output_Open_Ckt 1 "ERROR" 0 "No Error" ;
VAL_ 1294 DCDC_Low_Temp 1 "ERROR" 0 "No Error" ;
VAL_ 1294 DCDC_Input_Under_Vlt 1 "ERROR" 0 "No Error" ;
VAL_ 1294 DCDC_Input_Over_Vlt 1 "ERROR" 0 "No Error" ;
VAL_ 1294 DCDC_Input_Over_Curr 1 "ERROR" 0 "No Error" ;
VAL_ 1294 DCDC_High_Temp 1 "ERROR" 0 "No Error" ;
VAL_ 1294 DCDC_Output_Under_Vlt_Flt 1 "ERROR" 0 "No Error" ;
VAL_ 1294 DC_DC_Curr_Sensing_Fail 1 "ERROR" 0 "No Error" ;
VAL_ 1294 DCDC_Contactor_or_Relay_Fail 1 "ERROR" 0 "No Error" ;
VAL_ 1294 OBC_Output_Over_Vlt_Flt 1 "ERROR" 0 "No Error" ;
VAL_ 1294 OBC_Output_Shrt_Ckt_Fail 1 "ERROR" 0 "No Error" ;
VAL_ 1294 OBC_Output_Open_Ckt 1 "ERROR" 0 "No Error" ;
VAL_ 1294 OBC_Contactor_or_Relay_Fail 1 "ERROR" 0 "No Error" ;
VAL_ 1294 OBC_Curr_Sensing_Fail 1 "ERROR" 0 "No Error" ;
VAL_ 1294 OBC_Temp_Snsr_Fail 1 "ERROR" 0 "No Error" ;
VAL_ 1294 OBC_Low_temp 1 "ERROR" 0 "No Error" ;
VAL_ 1294 OBC_High_Temp 1 "ERROR" 0 "No Error" ;
VAL_ 1294 OBC_Output_Over_Curr 1 "ERROR" 0 "No Error" ;
VAL_ 1294 OBC_Input_Over_Curr 1 "ERROR" 0 "No Error" ;
VAL_ 1294 OBC_Input_AC_under_Vlt 1 "ERROR" 0 "No Error" ;
VAL_ 1294 OBC_Input_AC_Over_Vlt 1 "ERROR" 0 "No Error" ;
VAL_ 784 OBC_Wakeup 1 "Wakeup" 0 "Sleep" ;
VAL_ 784 PreChrg_Sts 2 "Failure" 1 "Success" 0 "SNA" ;
VAL_ 784 Heartbeat_Fail_From_BMS 1 "True" 0 "False" ;
VAL_ 784 Heartbeat_Fail_From_VCU 1 "True" 0 "False" ;
VAL_ 784 Chrgr_Mode 7 "Error" 6 "IP Volt Derating" 5 "FET Temp Derating" 4 "PCB Temp Derating" 3 "Charging" 2 "PreCharge" 1 "Standby" 0 "OFF" ;
VAL_ 784 Charger_Sts_Signal 1 "Ready" 0 "Not ready" ;
VAL_ 81 MDTC_Failure 1 "True" 0 "False" ;
VAL_ 81 MTC_Failure 1 "True" 0 "False" ;
VAL_ 81 Motor_Torque_Estimated_Val 1 "Valid" 0 "Not Valid" ;
VAL_ 81 MCU_Torque_Req_Val 1 "Valid" 0 "Not Valid" ;
VAL_ 81 Motor_RPM_Val 1 "Valid" 0 "Not Valid" ;
VAL_ 833 Bus_OFF_Err 1 "Error" 0 "No Error" ;
VAL_ 833 MCU_GD_Fail_Sts 1 "Error" 0 "No Error" ;
VAL_ 833 MCU_OnAxis_Fail_Sts 1 "Error" 0 "No Error" ;
VAL_ 833 MCU_SBC_G3_Flt 1 "Error" 0 "No Error" ;
VAL_ 833 MCU_GateDriver_G3_Flt 1 "Error" 0 "No Error" ;
VAL_ 833 MCU_GD_Int_b_Flt 1 "Error" 0 "No Error" ;
VAL_ 833 MCU_Unintended_Trq_Flt 1 "Error" 0 "No Error" ;
VAL_ 833 MCU_Phase_Curr_Sum_Flt 1 "Error" 0 "No Error" ;
VAL_ 833 MCU_Flt_On_Axis_G3_Failure 1 "Error" 0 "No Error" ;
VAL_ 833 MCU_Dio_Phase_Over_Curr_Sts 1 "Error" 0 "No Error" ;
VAL_ 833 MCU_SBC_Fail_Sts 1 "Error" 0 "No Error" ;
VAL_ 833 MCU_Dio_DC_Over_Curr_Flt 1 "Error" 0 "No Error" ;
VAL_ 833 MCU_MOSFET_Low_Temp_Flt 1 "Error" 0 "No Error" ;
VAL_ 833 Mcu_Flt_NVM_Vlt_Notstable 1 "ERROR" 0 "No Error" ;
VAL_ 833 MOSFET_over_Temp_Err 1 "ERROR" 0 "No Error" ;
VAL_ 833 MCU_over_Temp_Err 1 "ERROR" 0 "No Error" ;
VAL_ 833 Motor_over_Temp_Err 1 "ERROR" 0 "No Error" ;
VAL_ 833 MOSFET_over_Temp_Warn 1 "ERROR" 0 "No Error" ;
VAL_ 833 MCU_NVM_Vlt_ChkSm_Mismatch 1 "ERROR" 0 "No Error" ;
VAL_ 833 Mcu_Flt_PhaseOffsetErr 1 "ERROR" 0 "No Error" ;
VAL_ 833 Mcu_Flt_BuckConverter_UV 1 "ERROR" 0 "No Error" ;
VAL_ 833 Mcu_Flt_BuckConverter_STG 1 "ERROR" 0 "No Error" ;
VAL_ 833 Mcu_Flt_BuckConverter_STB 1 "ERROR" 0 "No Error" ;
VAL_ 833 Mcu_Flt_BuckConverter_OV 1 "ERROR" 0 "No Error" ;
VAL_ 833 LV_supplyUnderVlt 1 "ERROR" 0 "No Error" ;
VAL_ 833 LV_supplyOverVlt 1 "ERROR" 0 "No Error" ;
VAL_ 833 Throttle_ideal_per_Err 1 "ERROR" 0 "No Error" ;
VAL_ 833 MCU_Flt_MOSFET_STB 1 "ERROR" 0 "No Error" ;
VAL_ 833 MCU_Flt_MOSFET_STG 1 "ERROR" 0 "No Error" ;
VAL_ 833 Mcu_Flt_Rotor_Stall 1 "Fault" 0 "No fault" ;
VAL_ 833 Mcu_Flt_BoardTemp_Low 1 "Fault" 0 "No fault" ;
VAL_ 833 Mcu_Flt_MachineTemp_Low 1 "Fault" 0 "No fault" ;
VAL_ 833 MCU_dio_phase_ctrl_sts 1 "ERROR" 0 "No Error" ;
VAL_ 833 MCU_dio_over_curr_status 1 "Enable" 0 "Disable" ;
VAL_ 833 MCU_dio_over_volt_sts 1 "Enable" 0 "Disable" ;
VAL_ 833 Mcu_Flt_DCCurrentSnsrSTB 1 "Error" 0 "No Error" ;
VAL_ 833 Mcu_Flt_DCCurrentSnsrSTG 1 "Error" 0 "No Error" ;
VAL_ 833 MCU_Flt_MachineTempSnsrSTG 1 "ERROR" 0 "No Error" ;
VAL_ 833 MCU_Flt_MachineTempSnsrSTB 1 "ERROR" 0 "No Error" ;
VAL_ 833 Mcu_Flt_BphaseSTB 1 "Error" 0 "No Error" ;
VAL_ 833 Mcu_Flt_BphaseSTG 1 "Error" 0 "No Error" ;
VAL_ 833 Mcu_Flt_YphaseSTB 1 "Error" 0 "No Error" ;
VAL_ 833 Mcu_Flt_YphaseSTG 1 "Error" 0 "No Error" ;
VAL_ 833 Loss_of_VCU_Msg 1 "ERROR" 0 "No Error" ;
VAL_ 833 Mcu_Flt_RphaseSTB 1 "Error" 0 "No Error" ;
VAL_ 833 Mcu_Flt_RphaseSTG 1 "Error" 0 "No Error" ;
VAL_ 833 Mcu_Flt_BoardTempSnsrSTB 1 "Error" 0 "No Error" ;
VAL_ 833 Mcu_Flt_BoardTempSnsrSTG 1 "Error" 0 "No Error" ;
VAL_ 833 MCU_Flt_KL30_Snsr_STB 1 "ERROR" 0 "No Error" ;
VAL_ 833 MCU_Flt_KL30_Snsr_STG 1 "ERROR" 0 "No Error" ;
VAL_ 833 Mcu_Flt_DCBus_VoltgeSnsr_STB 1 "Error" 0 "No Error" ;
VAL_ 833 Mcu_Flt_DCBus_VltSnsr_STG 1 "Error" 0 "No Error" ;
VAL_ 833 MCU_Over_speed_Flt 1 "Error" 0 "No Error" ;
VAL_ 833 DCbus_OverCurr 1 "ERROR" 0 "No Error" ;
VAL_ 833 DCbus_OverVlt 1 "ERROR" 0 "No Error" ;
VAL_ 833 DCbus_UnderVlt 1 "ERROR" 0 "No Error" ;
VAL_ 833 Encoder_Fail 1 "ERROR" 0 "No Error" ;
VAL_ 833 MCU_Unintended_Direction 1 "Error" 0 "No Error" ;
VAL_ 833 Motor_over_temp_warn 1 "Error" 0 "No Error" ;
VAL_ 833 MCU_over_temp_warn 1 "Error" 0 "No Error" ;
VAL_ 833 Mcu_Flt_Wrong_Offset_Flt 1 "Error" 0 "No Error" ;
VAL_ 833 Motor_OC_protect_W_phase 1 "ERROR" 0 "No Error" ;
VAL_ 833 Motor_OC_protect_V_phase 1 "ERROR" 0 "No Error" ;
VAL_ 833 Motor_OC_protect_U_phase 1 "ERROR" 0 "No Error" ;
VAL_ 560 Active_DisChrg 3 "Invalid" 2 "Completed" 1 "InProgress" 0 "Not Active" ;
VAL_ 560 Hill_Hold_Sts 1 "Active" 0 "Not Active" ;
VAL_ 560 Cruise_Control_Status 1 "Active" 0 "Not Active" ;
VAL_ 560 MCU_Ride_Modes 10 "SNA" 9 "OFFROAD" 8 "REVERSE" 7 "CRAWL" 6 "LIMPHOME" 5 "CUSTOM" 4 "RAIN" 3 "SPORT" 2 "TOUR" 1 "ECO" 0 "PARK" ;
VAL_ 1288 BAL_Sts 1 "Active" 0 "Not Active" ;
VAL_ 1288 BMS_BAL_Sts_Batt_Cell_19 1 "ON" 0 "OFF" ;
VAL_ 1288 BMS_BAL_Sts_Batt_Cell_9 1 "ON" 0 "OFF" ;
VAL_ 1288 BMS_BAL_Sts_Batt_Cell_8 1 "ON" 0 "OFF" ;
VAL_ 1288 BMS_BAL_Sts_Batt_Cell_7 1 "ON" 0 "OFF" ;
VAL_ 1288 BMS_BAL_Sts_Batt_Cell_6 1 "ON" 0 "OFF" ;
VAL_ 1288 BMS_BAL_Sts_Batt_Cell_5 1 "ON" 0 "OFF" ;
VAL_ 1288 BMS_BAL_Sts_Batt_Cell_4 1 "ON" 0 "OFF" ;
VAL_ 1288 BMS_BAL_Sts_Batt_Cell_3 1 "ON" 0 "OFF" ;
VAL_ 1288 BMS_BAL_Sts_Batt_Cell_28 1 "ON" 0 "OFF" ;
VAL_ 1288 BMS_BAL_Sts_Batt_Cell_27 1 "ON" 0 "OFF" ;
VAL_ 1288 BMS_BAL_Sts_Batt_Cell_26 1 "ON" 0 "OFF" ;
VAL_ 1288 BMS_BAL_Sts_Batt_Cell_25 1 "ON" 0 "OFF" ;
VAL_ 1288 BMS_BAL_Sts_Batt_Cell_24 1 "ON" 0 "OFF" ;
VAL_ 1288 BMS_BAL_Sts_Batt_Cell_23 1 "ON" 0 "OFF" ;
VAL_ 1288 BMS_BAL_Sts_Batt_Cell_22 1 "ON" 0 "OFF" ;
VAL_ 1288 BMS_BAL_Sts_Batt_Cell_21 1 "ON" 0 "OFF" ;
VAL_ 1288 BMS_BAL_Sts_Batt_Cell_20 1 "ON" 0 "OFF" ;
VAL_ 1288 BMS_BAL_Sts_Batt_Cell_2 1 "ON" 0 "OFF" ;
VAL_ 1288 BMS_BAL_Sts_Batt_Cell_18 1 "ON" 0 "OFF" ;
VAL_ 1288 BMS_BAL_Sts_Batt_Cell_17 1 "ON" 0 "OFF" ;
VAL_ 1288 BMS_BAL_Sts_Batt_Cell_16 1 "ON" 0 "OFF" ;
VAL_ 1288 BMS_BAL_Sts_Batt_Cell_15 1 "ON" 0 "OFF" ;
VAL_ 1288 BMS_BAL_Sts_Batt_Cell_14 1 "ON" 0 "OFF" ;
VAL_ 1288 BMS_BAL_Sts_Batt_Cell_13 1 "ON" 0 "OFF" ;
VAL_ 1288 BMS_BAL_Sts_Batt_Cell_12 1 "ON" 0 "OFF" ;
VAL_ 1288 BMS_BAL_Sts_Batt_Cell_11 1 "ON" 0 "OFF" ;
VAL_ 1288 BMS_BAL_Sts_Batt_Cell_10 1 "ON" 0 "OFF" ;
VAL_ 1288 BMS_BAL_Sts_Batt_Cell_1 1 "ON" 0 "OFF" ;
VAL_ 298 BMS_G4_Type3_Flt 1 "True" 0 "False" ;
VAL_ 298 BMS_G4_Type2_Flt 1 "True" 0 "False" ;
VAL_ 298 BMS_G4_Type1_Flt 1 "True" 0 "False" ;
VAL_ 298 BMS_G3_Flt 1 "True" 0 "False" ;
VAL_ 298 BMS_G2_Flt 1 "True" 0 "False" ;
VAL_ 298 ASC_Prep_Flg 1 "True" 0 "False" ;
VAL_ 298 HVIL_OBC_Sts 1 "Success" 0 "Failure" ;
VAL_ 298 HVIL_MCU_Sts 1 "Success" 0 "Failure" ;
VAL_ 298 BMS_Regen_Inhibit 1 "True" 0 "False" ;
VAL_ 298 PreChrg_Contactor_state 2 "PRECHARGE_CONTACTOR_FAULT" 1 "CONNECTED

" 0 "DISCONNECTED

" ;
VAL_ 298 Chrg_Contactor_state 2 "NEGATIVE_CONTACTOR_FAULT" 1 "CONNECTED

" 0 "DISCONNECTED" ;
VAL_ 298 BMS_Mode 4 "BMS_FAULT" 3 "BMS_STANDBY

" 2 "BMS_CHARGE

" 1 "BMS_DISCHARGE

" 0 "BMS_SLEEP" ;
VAL_ 298 DisChrg_Contactor_state 5 "NEGATIVE_CONTACTOR_FAULT" 4 "POSITIVE_CONTACTOR_FAULT

" 3 "CONNECT_PENDING

" 2 "CONNECTED

" 1 "DISCONNECT_PENDING

" 0 "DISCONNECTED

" ;
VAL_ 301 Chrgr_Mode_Request 5 "Standby" 4 "CC End" 3 "Charge Complete" 2 "CV" 1 "CC" 0 "Charge Diasabled" ;
